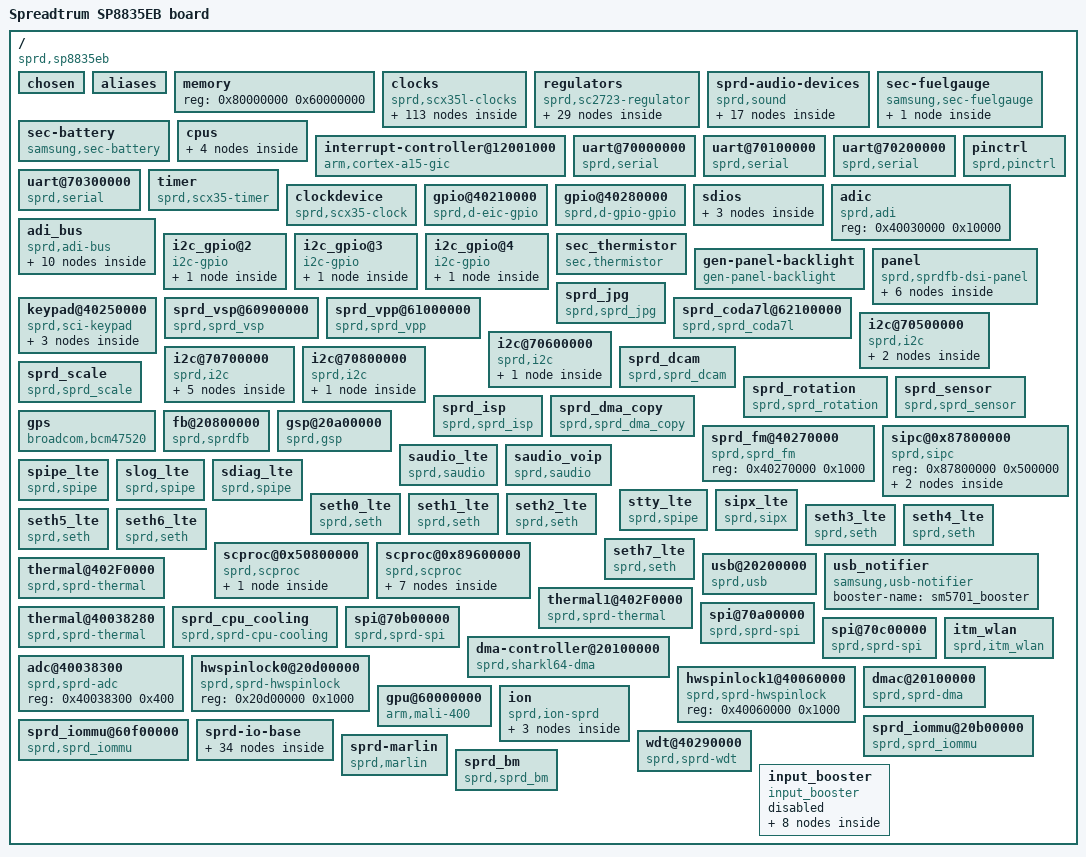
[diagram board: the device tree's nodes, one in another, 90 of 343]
/dts-v1/;

/memreserve/	0x0000000087800000 0x0000000000500000;
/memreserve/	0x0000000089600000 0x0000000004380000;
/memreserve/	0x000000009b23b000 0x0000000003939000;
/memreserve/	0x000000009eb74000 0x0000000000a8c000;
/memreserve/	0x000000009f600000 0x0000000000708000;
/ {
	#address-cells = <0x01>;
	#size-cells = <0x01>;
	model = "Spreadtrum SP8835EB board";
	compatible = "sprd,sp8835eb";
	sprd,sc-id = <0x2666 0x03 0x20000>;
	interrupt-parent = <0x01>;

	chosen {
		bootargs = "loglevel=1 init=/init root=/dev/ram0 rw";
		linux,initrd-start = <0x85500000>;
		linux,initrd-end = <0x855a3212>;
	};

	aliases {
		serial0 = "/uart@70000000";
		serial1 = "/uart@70100000";
		serial2 = "/uart@70200000";
		serial3 = "/uart@70300000";
		i2c0 = "/i2c@70500000";
		i2c1 = "/i2c@70600000";
		i2c2 = "/i2c@70700000";
		i2c3 = "/i2c@70800000";
		lcd0 = "/fb@20800000";
		spi0 = "/spi@70a00000";
		spi1 = "/spi@70b00000";
		spi2 = "/spi@70c00000";
		hwspinlock0 = "/hwspinlock0@20d00000";
		hwspinlock1 = "/hwspinlock1@40060000";
		i2c_gpio7 = "/i2c_gpio@2";
		i2c_gpio8 = "/i2c_gpio@3";
		i2c_gpio9 = "/i2c_gpio@4";
	};

	memory {
		#address-cells = <0x01>;
		#size-cells = <0x01>;
		device_type = "memory";
		reg = <0x80000000 0x60000000>;
	};

	clocks {
		compatible = "sprd,scx35l-clocks";
		#address-cells = <0x01>;
		#size-cells = <0x01>;

		ext_26m {
			compatible = "sprd,fixed-clock";
			#clock-cells = <0x00>;
			clock-frequency = <0x18cba80>;
			clock-output-names = "ext_26m";
			linux,phandle = <0x07>;
			phandle = <0x07>;
		};

		ext_32k {
			compatible = "sprd,fixed-clock";
			#clock-cells = <0x00>;
			clock-frequency = <0x8000>;
			clock-output-names = "ext_32k";
			linux,phandle = <0x11>;
			phandle = <0x11>;
		};

		ext_26m_rf1 {
			compatible = "sprd,fixed-clock";
			#clock-cells = <0x00>;
			clock-frequency = <0x18cba80>;
			clock-output-names = "ext_26m_rf1";
			linux,phandle = <0x12>;
			phandle = <0x12>;
		};

		ext_1m {
			compatible = "sprd,fixed-clock";
			#clock-cells = <0x00>;
			clock-frequency = <0xf4240>;
			clock-output-names = "ext_1m";
			linux,phandle = <0x18>;
			phandle = <0x18>;
		};

		ext_2m {
			compatible = "sprd,fixed-clock";
			#clock-cells = <0x00>;
			clock-frequency = <0x1e8480>;
			clock-output-names = "ext_2m";
		};

		ext_4m {
			compatible = "sprd,fixed-clock";
			#clock-cells = <0x00>;
			clock-frequency = <0x3d0900>;
			clock-output-names = "ext_4m";
			linux,phandle = <0x0b>;
			phandle = <0x0b>;
		};

		clk_pad {
			compatible = "sprd,fixed-clock";
			#clock-cells = <0x00>;
			clock-frequency = <0x3d09000>;
			clock-output-names = "clk_pad";
			linux,phandle = <0x28>;
			phandle = <0x28>;
		};

		clk_mpll {
			compatible = "sprd,adjustable-pll-clock";
			#clock-cells = <0x00>;
			reg = <0x402e0044 0x7ff 0x402b0094 0x01>;
			clock-output-names = "clk_mpll";
			linux,phandle = <0x04>;
			phandle = <0x04>;
		};

		clk_dpll {
			compatible = "sprd,adjustable-pll-clock";
			#clock-cells = <0x00>;
			reg = <0x402e004c 0x7ff 0x402b0098 0x01>;
			clock-output-names = "clk_dpll";
			linux,phandle = <0x03>;
			phandle = <0x03>;
		};

		clk_ltepll {
			compatible = "sprd,adjustable-pll-clock";
			#clock-cells = <0x00>;
			reg = <0x402e005c 0x7ff 0x402b009c 0x01>;
			clock-output-names = "clk_ltepll";
			linux,phandle = <0x05>;
			phandle = <0x05>;
		};

		clk_twpll {
			compatible = "sprd,adjustable-pll-clock";
			#clock-cells = <0x00>;
			reg = <0x402e0054 0x7ff 0x402b00a0 0x01>;
			clock-output-names = "clk_twpll";
			linux,phandle = <0x02>;
			phandle = <0x02>;
		};

		clk_lvdspll {
			compatible = "sprd,adjustable-pll-clock";
			#clock-cells = <0x00>;
			reg = <0x402e0064 0x7ff 0x402b00a4 0x01>;
			clock-output-names = "clk_lvdspll";
			linux,phandle = <0x06>;
			phandle = <0x06>;
		};

		clk_768m {
			compatible = "sprd,fixed-factor-clock";
			#clock-cells = <0x00>;
			clock-mult = <0x01>;
			clock-div = <0x02>;
			clocks = <0x02>;
			clock-output-names = "clk_768m";
			linux,phandle = <0x09>;
			phandle = <0x09>;
		};

		clk_512m {
			compatible = "sprd,fixed-factor-clock";
			#clock-cells = <0x00>;
			clock-mult = <0x01>;
			clock-div = <0x03>;
			clocks = <0x02>;
			clock-output-names = "clk_512m";
			linux,phandle = <0x08>;
			phandle = <0x08>;
		};

		clk_384m {
			compatible = "sprd,fixed-factor-clock";
			#clock-cells = <0x00>;
			clock-mult = <0x01>;
			clock-div = <0x04>;
			clocks = <0x02>;
			clock-output-names = "clk_384m";
			linux,phandle = <0x1c>;
			phandle = <0x1c>;
		};

		clk_312m {
			compatible = "sprd,fixed-factor-clock";
			#clock-cells = <0x00>;
			clock-mult = <0x01>;
			clock-div = <0x05>;
			clocks = <0x02>;
			clock-output-names = "clk_312m";
			linux,phandle = <0x26>;
			phandle = <0x26>;
		};

		clk_307m2 {
			compatible = "sprd,fixed-factor-clock";
			#clock-cells = <0x00>;
			clock-mult = <0x01>;
			clock-div = <0x05>;
			clocks = <0x02>;
			clock-output-names = "clk_307m2";
			linux,phandle = <0x1b>;
			phandle = <0x1b>;
		};

		clk_256m {
			compatible = "sprd,fixed-factor-clock";
			#clock-cells = <0x00>;
			clock-mult = <0x01>;
			clock-div = <0x06>;
			clocks = <0x02>;
			clock-output-names = "clk_256m";
			linux,phandle = <0x20>;
			phandle = <0x20>;
		};

		clk_192m {
			compatible = "sprd,fixed-factor-clock";
			#clock-cells = <0x00>;
			clock-mult = <0x01>;
			clock-div = <0x08>;
			clocks = <0x02>;
			clock-output-names = "clk_192m";
			linux,phandle = <0x1a>;
			phandle = <0x1a>;
		};

		clk_153m6 {
			compatible = "sprd,fixed-factor-clock";
			#clock-cells = <0x00>;
			clock-mult = <0x01>;
			clock-div = <0x0a>;
			clocks = <0x02>;
			clock-output-names = "clk_153m6";
			linux,phandle = <0x19>;
			phandle = <0x19>;
		};

		clk_128m {
			compatible = "sprd,fixed-factor-clock";
			#clock-cells = <0x00>;
			clock-mult = <0x01>;
			clock-div = <0x0c>;
			clocks = <0x02>;
			clock-output-names = "clk_128m";
			linux,phandle = <0x0d>;
			phandle = <0x0d>;
		};

		clk_96m {
			compatible = "sprd,fixed-factor-clock";
			#clock-cells = <0x00>;
			clock-mult = <0x01>;
			clock-div = <0x10>;
			clocks = <0x02>;
			clock-output-names = "clk_96m";
			linux,phandle = <0x0c>;
			phandle = <0x0c>;
		};

		clk_76m8 {
			compatible = "sprd,fixed-factor-clock";
			#clock-cells = <0x00>;
			clock-mult = <0x01>;
			clock-div = <0x14>;
			clocks = <0x02>;
			clock-output-names = "clk_76m8";
			linux,phandle = <0x0e>;
			phandle = <0x0e>;
		};

		clk_64m {
			compatible = "sprd,fixed-factor-clock";
			#clock-cells = <0x00>;
			clock-mult = <0x01>;
			clock-div = <0x18>;
			clocks = <0x02>;
			clock-output-names = "clk_64m";
			linux,phandle = <0x1f>;
			phandle = <0x1f>;
		};

		clk_51m2 {
			compatible = "sprd,fixed-factor-clock";
			#clock-cells = <0x00>;
			clock-mult = <0x01>;
			clock-div = <0x1e>;
			clocks = <0x02>;
			clock-output-names = "clk_51m2";
			linux,phandle = <0x10>;
			phandle = <0x10>;
		};

		clk_48m {
			compatible = "sprd,fixed-factor-clock";
			#clock-cells = <0x00>;
			clock-mult = <0x01>;
			clock-div = <0x20>;
			clocks = <0x02>;
			clock-output-names = "clk_48m";
			linux,phandle = <0x14>;
			phandle = <0x14>;
		};

		clk_38m4 {
			compatible = "sprd,fixed-factor-clock";
			#clock-cells = <0x00>;
			clock-mult = <0x01>;
			clock-div = <0x28>;
			clocks = <0x02>;
			clock-output-names = "clk_38m4";
			linux,phandle = <0x0f>;
			phandle = <0x0f>;
		};

		clk_24m {
			compatible = "sprd,fixed-factor-clock";
			#clock-cells = <0x00>;
			clock-mult = <0x01>;
			clock-div = <0x40>;
			clocks = <0x02>;
			clock-output-names = "clk_24m";
			linux,phandle = <0x22>;
			phandle = <0x22>;
		};

		clk_12m {
			compatible = "sprd,fixed-factor-clock";
			#clock-cells = <0x00>;
			clock-mult = <0x01>;
			clock-div = <0x80>;
			clocks = <0x02>;
			clock-output-names = "clk_12m";
			linux,phandle = <0x21>;
			phandle = <0x21>;
		};

		clk_42m_d {
			compatible = "sprd,fixed-factor-clock";
			#clock-cells = <0x00>;
			clock-mult = <0x01>;
			clock-div = <0x20>;
			clocks = <0x03>;
			clock-output-names = "clk_42m_d";
			linux,phandle = <0x13>;
			phandle = <0x13>;
		};

		clk_56m_m {
			compatible = "sprd,fixed-factor-clock";
			#clock-cells = <0x00>;
			clock-mult = <0x01>;
			clock-div = <0x20>;
			clocks = <0x04>;
			clock-output-names = "clk_56m_m";
			linux,phandle = <0x15>;
			phandle = <0x15>;
		};

		clk_38m4_lte {
			compatible = "sprd,fixed-factor-clock";
			#clock-cells = <0x00>;
			clock-mult = <0x01>;
			clock-div = <0x20>;
			clocks = <0x05>;
			clock-output-names = "clk_38m4_lte";
			linux,phandle = <0x16>;
			phandle = <0x16>;
		};

		clk_44m_lvds {
			compatible = "sprd,fixed-factor-clock";
			#clock-cells = <0x00>;
			clock-mult = <0x01>;
			clock-div = <0x20>;
			clocks = <0x06>;
			clock-output-names = "clk_44m_lvds";
			linux,phandle = <0x17>;
			phandle = <0x17>;
		};

		clk_614m4 {
			compatible = "sprd,fixed-factor-clock";
			#clock-cells = <0x00>;
			clock-mult = <0x01>;
			clock-div = <0x02>;
			clocks = <0x05>;
			clock-output-names = "clk_614m4";
			linux,phandle = <0x1d>;
			phandle = <0x1d>;
		};

		clk_mcu {
			compatible = "sprd,composite-dev-clock";
			#clock-cells = <0x00>;
			reg = <0x20e00054 0x07 0x20e00038 0x70>;
			clocks = <0x07 0x08 0x09 0x03 0x05 0x02 0x04>;
			clock-output-names = "clk_mcu";
			linux,phandle = <0x0a>;
			phandle = <0x0a>;
		};

		clk_ca7_axi {
			compatible = "sprd,divider-clock";
			#clock-cells = <0x00>;
			reg = <0x20e00038 0x700>;
			clocks = <0x0a>;
			clock-output-names = "clk_ca7_axi";
		};

		clk_ca7_dbg {
			compatible = "sprd,divider-clock";
			#clock-cells = <0x00>;
			reg = <0x20e00038 0x70000>;
			clocks = <0x0a>;
			clock-output-names = "clk_ca7_dbg";
		};

		clk_pub_ahb {
			compatible = "sprd,composite-dev-clock";
			#clock-cells = <0x00>;
			reg = <0x402d0020 0x03 0x402d0020 0x300>;
			clocks = <0x07 0x0b 0x0c 0x0d>;
			clock-output-names = "clk_pub_ahb";
		};

		clk_aon_apb {
			compatible = "sprd,composite-dev-clock";
			#clock-cells = <0x00>;
			reg = <0x402d0024 0x03 0x402d0024 0x300>;
			clocks = <0x0b 0x07 0x0e 0x0c>;
			clock-output-names = "clk_aon_apb";
			linux,phandle = <0x1e>;
			phandle = <0x1e>;
		};

		clk_adi {
			compatible = "sprd,muxed-clock";
			#clock-cells = <0x00>;
			reg = <0x402d0028 0x03 0x402e0000 0x10000>;
			clocks = <0x07 0x0b 0x0f 0x10>;
			clock-output-names = "clk_adi";
		};

		clk_aux0 {
			compatible = "sprd,muxed-clock";
			#clock-cells = <0x00>;
			reg = <0x402e0088 0x0f 0x402e0004 0x04>;
			clocks = <0x11 0x07 0x12 0x0b 0x13 0x14 0x15>;
			clock-output-names = "clk_aux0";
		};

		clk_aux1 {
			compatible = "sprd,muxed-clock";
			#clock-cells = <0x00>;
			reg = <0x402d0088 0xf0 0x402e0004 0x08>;
			clocks = <0x11 0x07 0x12 0x0b 0x13 0x14 0x15 0x16 0x17>;
			clock-output-names = "clk_aux1";
		};

		clk_aux2 {
			compatible = "sprd,muxed-clock";
			#clock-cells = <0x00>;
			reg = <0x402d0088 0xf00 0x402e0004 0x10>;
			clocks = <0x11 0x07 0x12 0x0b 0x13 0x14 0x15 0x16 0x17>;
			clock-output-names = "clk_aux2";
		};

		clk_pwm0 {
			compatible = "sprd,muxed-clock";
			#clock-cells = <0x00>;
			reg = <0x402d002c 0x03 0x402e0000 0x10>;
			clocks = <0x11 0x07 0x12 0x14>;
			clock-output-names = "clk_pwm0";
		};

		clk_pwm1 {
			compatible = "sprd,muxed-clock";
			#clock-cells = <0x00>;
			reg = <0x402d0030 0x03 0x402e0000 0x20>;
			clocks = <0x11 0x07 0x12 0x14>;
			clock-output-names = "clk_pwm1";
		};

		clk_pwm2 {
			compatible = "sprd,muxed-clock";
			#clock-cells = <0x00>;
			reg = <0x402d0034 0x03 0x402e0000 0x40>;
			clocks = <0x11 0x07 0x12 0x14>;
			clock-output-names = "clk_pwm2";
		};

		clk_pwm3 {
			compatible = "sprd,muxed-clock";
			#clock-cells = <0x00>;
			reg = <0x402d0038 0x03 0x402e0000 0x80>;
			clocks = <0x11 0x07 0x12 0x14>;
			clock-output-names = "clk_pwm3";
		};

		clk_thm {
			compatible = "sprd,muxed-clock";
			#clock-cells = <0x00>;
			reg = <0x402d0040 0x01 0x402e0004 0x02>;
			clocks = <0x11 0x18>;
			clock-output-names = "clk_thm";
		};

		clk_mspi {
			compatible = "sprd,muxed-clock";
			#clock-cells = <0x00>;
			reg = <0x402d0044 0x03 0x402e0000 0x800000>;
			clocks = <0x07 0x10 0x0e 0x0c>;
			clock-output-names = "clk_mspi";
		};

		clk_i2c {
			compatible = "sprd,muxed-clock";
			#clock-cells = <0x00>;
			reg = <0x402d0048 0x03 0x402e0000 0x80000000>;
			clocks = <0x07 0x14 0x10 0x19>;
			clock-output-names = "clk_i2c";
		};

		clk_avs {
			compatible = "sprd,muxed-clock";
			#clock-cells = <0x00>;
			reg = <0x402d004c 0x03 0x402e0004 0x40>;
			clocks = <0x07 0x14 0x10 0x0c>;
			clock-output-names = "clk_avs";
		};

		clk_audif {
			compatible = "sprd,muxed-clock";
			#clock-cells = <0x00>;
			reg = <0x402d0050 0x03 0x402e0000 0x20000>;
			clocks = <0x07 0x0f 0x10>;
			clock-output-names = "clk_audif";
		};

		clk_ca7_dap {
			compatible = "sprd,muxed-clock";
			#clock-cells = <0x00>;
			reg = <0x402d0054 0x03 0x402e0000 0x40000000>;
			clocks = <0x07 0x0e 0x0d 0x19>;
			clock-output-names = "clk_ca7_dap";
		};

		clk_emc {
			compatible = "sprd,composite-dev-clock";
			#clock-cells = <0x00>;
			reg = <0x402d0058 0x07 0x402d0058 0x700>;
			clocks = <0x07 0x1a 0x1b 0x1c 0x08 0x1d 0x09 0x03>;
			clock-output-names = "clk_emc";
		};

		clk_ca7_ts {
			compatible = "sprd,muxed-clock";
			#clock-cells = <0x00>;
			reg = <0x402d005c 0x03 0x402e0000 0x10000000>;
			clocks = <0x11 0x07 0x0d 0x19>;
			clock-output-names = "clk_ca7_ts";
		};

		clk_djtag_tck {
			compatible = "sprd,muxed-clock";
			#clock-cells = <0x00>;
			reg = <0x402d0060 0x01>;
			clocks = <0x07 0x0b>;
			clock-output-names = "clk_djtag_tck";
		};

		clk_arm7_ahb {
			compatible = "sprd,composite-dev-clock";
			#clock-cells = <0x00>;
			reg = <0x402d0064 0x03 0x402d0064 0x300>;
			clocks = <0x0b 0x07 0x0c 0x0d>;
			clock-output-names = "clk_arm7_ahb";
		};

		clk_ca5_ts {
			compatible = "sprd,muxed-clock";
			#clock-cells = <0x00>;
			reg = <0x402d0068 0x03 0x402e0004 0x4000000>;
			clocks = <0x11 0x07 0x0d 0x19>;
			clock-output-names = "clk_ca5_ts";
		};

		clk_disp_emc {
			compatible = "sprd,gate-clock";
			#clock-cells = <0x00>;
			reg = <0x402e0004 0x800>;
			clocks = <0x1e>;
			clock-output-names = "clk_disp_emc";
			linux,phandle = <0x4e>;
			phandle = <0x4e>;
		};

		clk_gsp_emc {
			compatible = "sprd,gate-clock";
			#clock-cells = <0x00>;
			reg = <0x402e0004 0x2000>;
			clocks = <0x1e>;
			clock-output-names = "clk_gsp_emc";
			linux,phandle = <0x51>;
			phandle = <0x51>;
		};

		clk_ap_ahb {
			compatible = "sprd,muxed-clock";
			#clock-cells = <0x00>;
			reg = <0x21500020 0x03>;
			clocks = <0x07 0x0e 0x0d 0x1a>;
			clock-output-names = "clk_ap_ahb";
		};

		clk_ap_apb {
			compatible = "sprd,muxed-clock";
			#clock-cells = <0x00>;
			reg = <0x21500024 0x03>;
			clocks = <0x07 0x1f 0x0c 0x0d>;
			clock-output-names = "clk_ap_apb";
		};

		clk_gsp {
			compatible = "sprd,muxed-clock";
			#clock-cells = <0x00>;
			reg = <0x21500028 0x03 0x20e00000 0x08>;
			clocks = <0x0c 0x19 0x1a 0x20>;
			clock-output-names = "clk_gsp";
			linux,phandle = <0x50>;
			phandle = <0x50>;
		};

		clk_dispc0 {
			compatible = "sprd,composite-dev-clock";
			#clock-cells = <0x00>;
			reg = <0x2150002c 0x03 0x2150002c 0x700 0x20e00000 0x02>;
			clocks = <0x19 0x1a 0x20 0x1b>;
			clock-output-names = "clk_dispc0";
			linux,phandle = <0x4b>;
			phandle = <0x4b>;
		};

		clk_dispc0_dbi {
			compatible = "sprd,composite-dev-clock";
			#clock-cells = <0x00>;
			reg = <0x21500030 0x03 0x21500030 0x700>;
			clocks = <0x0d 0x19 0x1a 0x20>;
			clock-output-names = "clk_dispc0_dbi";
			linux,phandle = <0x4c>;
			phandle = <0x4c>;
		};

		clk_dispc0_dpi {
			compatible = "sprd,composite-dev-clock";
			#clock-cells = <0x00>;
			reg = <0x21500034 0x03 0x21500034 0xff00>;
			clocks = <0x0d 0x19 0x1a 0x1c>;
			clock-output-names = "clk_dispc0_dpi";
			linux,phandle = <0x4d>;
			phandle = <0x4d>;
		};

		clk_nandc_ecc {
			compatible = "sprd,muxed-clock";
			#clock-cells = <0x00>;
			reg = <0x21500038 0x01 0x20e00000 0x80000 0x20e00000 0x20000>;
			clocks = <0x19 0x1a>;
			clock-output-names = "clk_nandc_ecc";
		};

		clk_nandc_2x {
			compatible = "sprd,composite-dev-clock";
			#clock-cells = <0x00>;
			reg = <0x20e03038 0x03 0x20e03038 0x0c 0x20e00000 0xe0000>;
			clocks = <0x1a 0x20 0x1b 0x1c>;
			clock-output-names = "clk_nandc_2x";
		};

		clk_sdio0 {
			compatible = "sprd,composite-dev-clock";
			#clock-cells = <0x00>;
			reg = <0x2150003c 0x03 0x2150003c 0x700 0x20e00000 0x100>;
			clocks = <0x07 0x20 0x1b 0x1c>;
			clock-output-names = "clk_sdio0";
			linux,phandle = <0x38>;
			phandle = <0x38>;
		};

		clk_sdio1 {
			compatible = "sprd,muxed-clock";
			#clock-cells = <0x00>;
			reg = <0x21500040 0x03 0x20e00000 0x200>;
			clocks = <0x14 0x0e 0x0c 0x0d>;
			clock-output-names = "clk_sdio1";
			linux,phandle = <0x39>;
			phandle = <0x39>;
		};

		clk_sdio2 {
			compatible = "sprd,muxed-clock";
			#clock-cells = <0x00>;
			reg = <0x21500044 0x03 0x20e00000 0x400>;
			clocks = <0x14 0x0e 0x0c 0x0d>;
			clock-output-names = "clk_sdio2";
		};

		clk_emmc {
			compatible = "sprd,muxed-clock";
			#clock-cells = <0x00>;
			reg = <0x21500048 0x03 0x20e00000 0x800>;
			clocks = <0x07 0x20 0x1b 0x1c>;
			clock-output-names = "clk_emmc";
			linux,phandle = <0x37>;
			phandle = <0x37>;
		};

		clk_otg_ref {
			compatible = "sprd,muxed-clock";
			#clock-cells = <0x00>;
			reg = <0x2150004c 0x01 0x20e00000 0x10>;
			clocks = <0x21 0x22>;
			clock-output-names = "clk_otg_ref";
		};

		clk_hsic_ref {
			compatible = "sprd,muxed-clock";
			#clock-cells = <0x00>;
			reg = <0x21500050 0x01 0x20e00000 0x04>;
			clocks = <0x21 0x22>;
			clock-output-names = "clk_hsic_ref";
		};

		clk_uart0 {
			compatible = "sprd,composite-dev-clock";
			#clock-cells = <0x00>;
			reg = <0x21500054 0x03 0x21500054 0x700 0x71300000 0x2000>;
			clocks = <0x07 0x14 0x10 0x0c>;
			clock-output-names = "clk_uart0";
		};

		clk_uart1 {
			compatible = "sprd,composite-dev-clock";
			#clock-cells = <0x00>;
			reg = <0x21500058 0x03 0x21500058 0x700 0x71300000 0x4000>;
			clocks = <0x07 0x14 0x10 0x0c>;
			clock-output-names = "clk_uart1";
		};

		clk_uart2 {
			compatible = "sprd,composite-dev-clock";
			#clock-cells = <0x00>;
			reg = <0x2150005c 0x03 0x2150005c 0x700 0x71300000 0x8000>;
			clocks = <0x07 0x14 0x10 0x0c>;
			clock-output-names = "clk_uart2";
		};

		clk_uart3 {
			compatible = "sprd,composite-dev-clock";
			#clock-cells = <0x00>;
			reg = <0x21500060 0x03 0x21500060 0x700 0x71300000 0x10000>;
			clocks = <0x07 0x14 0x10 0x0c>;
			clock-output-names = "clk_uart3";
		};

		clk_uart4 {
			compatible = "sprd,composite-dev-clock";
			#clock-cells = <0x00>;
			reg = <0x21500064 0x03 0x21500064 0x700 0x71300000 0x20000>;
			clocks = <0x07 0x14 0x10 0x0c>;
			clock-output-names = "clk_uart4";
		};

		clk_i2c0 {
			compatible = "sprd,composite-dev-clock";
			#clock-cells = <0x00>;
			reg = <0x21500068 0x03 0x21500068 0x700 0x71300000 0x100>;
			clocks = <0x07 0x14 0x10 0x19>;
			clock-output-names = "clk_i2c0";
		};

		clk_i2c1 {
			compatible = "sprd,composite-dev-clock";
			#clock-cells = <0x00>;
			reg = <0x2150006c 0x03 0x2150006c 0x700 0x71300000 0x200>;
			clocks = <0x07 0x14 0x10 0x19>;
			clock-output-names = "clk_i2c1";
		};

		clk_i2c2 {
			compatible = "sprd,composite-dev-clock";
			#clock-cells = <0x00>;
			reg = <0x21500070 0x03 0x21500070 0x700 0x71300000 0x400>;
			clocks = <0x07 0x14 0x10 0x19>;
			clock-output-names = "clk_i2c2";
		};

		clk_i2c3 {
			compatible = "sprd,composite-dev-clock";
			#clock-cells = <0x00>;
			reg = <0x21500074 0x03 0x21500074 0x700 0x71300000 0x800>;
			clocks = <0x07 0x14 0x10 0x19>;
			clock-output-names = "clk_i2c3";
		};

		clk_i2c4 {
			compatible = "sprd,composite-dev-clock";
			#clock-cells = <0x00>;
			reg = <0x21500078 0x03 0x21500078 0x700 0x71300000 0x1000>;
			clocks = <0x07 0x14 0x10 0x19>;
			clock-output-names = "clk_i2c4";
		};

		clk_spi0 {
			compatible = "sprd,composite-dev-clock";
			#clock-cells = <0x00>;
			reg = <0x2150007c 0x03 0x2150007c 0x700 0x71300000 0x20>;
			clocks = <0x07 0x0c 0x19 0x1a>;
			clock-output-names = "clk_spi0";
		};

		clk_spi1 {
			compatible = "sprd,composite-dev-clock";
			#clock-cells = <0x00>;
			reg = <0x21500080 0x03 0x21500080 0x700 0x71300000 0x40>;
			clocks = <0x07 0x0c 0x19 0x1a>;
			clock-output-names = "clk_spi1";
		};

		clk_spi2 {
			compatible = "sprd,composite-dev-clock";
			#clock-cells = <0x00>;
			reg = <0x21500084 0x03 0x21500084 0x700 0x71300000 0x80>;
			clocks = <0x07 0x0c 0x19 0x1a>;
			clock-output-names = "clk_spi2";
			linux,phandle = <0x4f>;
			phandle = <0x4f>;
		};

		clk_iis0 {
			compatible = "sprd,composite-dev-clock";
			#clock-cells = <0x00>;
			reg = <0x21500088 0x03 0x21500088 0x700 0x71300000 0x02>;
			clocks = <0x07 0x0d 0x19>;
			clock-output-names = "clk_iis0";
		};

		clk_iis1 {
			compatible = "sprd,composite-dev-clock";
			#clock-cells = <0x00>;
			reg = <0x2150008c 0x03 0x2150008c 0x700 0x71300000 0x04>;
			clocks = <0x07 0x0d 0x19>;
			clock-output-names = "clk_iis1";
		};

		clk_iis2 {
			compatible = "sprd,composite-dev-clock";
			#clock-cells = <0x00>;
			reg = <0x21500090 0x03 0x21500090 0x700 0x71300000 0x08>;
			clocks = <0x07 0x0d 0x19>;
			clock-output-names = "clk_iis2";
		};

		clk_iis3 {
			compatible = "sprd,composite-dev-clock";
			#clock-cells = <0x00>;
			reg = <0x21500094 0x03 0x21500094 0x700 0x71300000 0x10>;
			clocks = <0x07 0x0d 0x19>;
			clock-output-names = "clk_iis3";
		};

		clk_zipenc {
			compatible = "sprd,muxed-clock";
			#clock-cells = <0x00>;
			reg = <0x21500098 0x03 0x20e00000 0x100000>;
			clocks = <0x0c 0x19 0x1a 0x20>;
			clock-output-names = "clk_zipenc";
		};

		clk_zipdec {
			compatible = "sprd,muxed-clock";
			#clock-cells = <0x00>;
			reg = <0x2150009c 0x03 0x20e00000 0x200000>;
			clocks = <0x0c 0x19 0x1a 0x20>;
			clock-output-names = "clk_zipdec";
		};

		clk_gpu_axi {
			compatible = "sprd,gate-clock";
			#clock-cells = <0x00>;
			reg = <0x402e0000 0x8000000 0x402b0021 0x2000000>;
			clocks = <0x1e>;
			clock-output-names = "clk_gpu_axi";
			linux,phandle = <0x53>;
			phandle = <0x53>;
		};

		clk_gpu {
			compatible = "sprd,composite-dev-clock";
			#clock-cells = <0x00>;
			reg = <0x60100004 0x07 0x60100004 0x30>;
			clocks = <0x19 0x1a 0x20 0x1b 0x1c 0x08>;
			clock-output-names = "clk_gpu";
			linux,phandle = <0x54>;
			phandle = <0x54>;
		};

		clk_mm {
			compatible = "sprd,gate-clock";
			#clock-cells = <0x00>;
			reg = <0x402e0000 0x2000000 0x402b001d 0x2000000>;
			clocks = <0x1e>;
			clock-output-names = "clk_mm";
			linux,phandle = <0x23>;
			phandle = <0x23>;
		};

		clk_mm_ahb {
			compatible = "sprd,muxed-clock";
			#clock-cells = <0x00>;
			reg = <0x60e00020 0x03>;
			clocks = <0x07 0x0c 0x0d 0x19>;
			clock-output-names = "clk_mm_ahb";
			mm-domain;
			linux,phandle = <0x25>;
			phandle = <0x25>;
		};

		clk_mm_axi {
			compatible = "sprd,gate-clock";
			#clock-cells = <0x00>;
			reg = <0x60d00008 0x80>;
			clocks = <0x23>;
			clock-output-names = "clk_mm_axi";
			#mm-domain;
			linux,phandle = <0x24>;
			phandle = <0x24>;
		};

		clk_mm_mtx_axi {
			compatible = "sprd,gate-clock";
			#clock-cells = <0x00>;
			reg = <0x60d00008 0x100>;
			clocks = <0x24>;
			clock-output-names = "clk_mm_mtx_axi";
			mm-domain;
		};

		clk_mmu {
			compatible = "sprd,gate-clock";
			#clock-cells = <0x00>;
			reg = <0x60d00000 0x80>;
			clocks = <0x25>;
			clock-output-names = "clk_mmu";
			mm-domain;
			linux,phandle = <0x55>;
			phandle = <0x55>;
		};

		clk_mm_ckg {
			compatible = "sprd,gate-clock";
			#clock-cells = <0x00>;
			reg = <0x60d00000 0x40>;
			clocks = <0x25>;
			clock-output-names = "clk_mm_ckg";
			mm-domain;
		};

		clk_jpg {
			compatible = "sprd,muxed-clock";
			#clock-cells = <0x00>;
			reg = <0x60e00038 0x03 0x60d00008 0x40 0x60d00000 0x20>;
			clocks = <0x0e 0x0d 0x20 0x26>;
			clock-output-names = "clk_jpg";
			mm-domain;
			linux,phandle = <0x41>;
			phandle = <0x41>;
		};

		clk_vpp {
			compatible = "sprd,muxed-clock";
			#clock-cells = <0x00>;
			reg = <0x60e00048 0x03 0x60d00008 0x200 0x60d00000 0x100>;
			clocks = <0x0e 0x0d 0x1a 0x20>;
			clock-output-names = "clk_vpp";
			mm-domain;
			linux,phandle = <0x42>;
			phandle = <0x42>;
		};

		clk_coda7_axi {
			compatible = "sprd,muxed-clock";
			#clock-cells = <0x00>;
			reg = <0x62000008 0x300 0x62000004 0x01 0x402e0004 0x10000000>;
			clocks = <0x0e 0x0d 0x19 0x1a>;
			clock-output-names = "clk_coda7_axi";
			mm_domain;
			linux,phandle = <0x43>;
			phandle = <0x43>;
		};

		clk_coda7_cc {
			compatible = "sprd,muxed-clock";
			#clock-cells = <0x00>;
			reg = <0x62000008 0x30 0x62000004 0x02 0x402e0004 0x10000000>;
			clocks = <0x0e 0x0d 0x19 0x1a>;
			clock-output-names = "clk_coda7_cc";
			mm_domain;
			linux,phandle = <0x44>;
			phandle = <0x44>;
		};

		clk_coda7_apb {
			compatible = "sprd,muxed-clock";
			#clock-cells = <0x00>;
			reg = <0x62000008 0x03 0x62000004 0x10 0x402e0004 0x10000000>;
			clocks = <0x07 0x0e 0x0c 0x0d>;
			clock-output-names = "clk_coda7_apb";
			mm_domain;
			linux,phandle = <0x45>;
			phandle = <0x45>;
		};

		clk_csi {
			compatible = "sprd,gate-clock";
			#clock-cells = <0x00>;
			reg = <0x60d00008 0x02 0x60d00000 0x10>;
			clocks = <0x25>;
			clock-output-names = "clk_csi";
			mm-domain;
			linux,phandle = <0x27>;
			phandle = <0x27>;
		};

		clk_dcam_mipi {
			compatible = "sprd,gate-clock";
			#clock-cells = <0x00>;
			reg = <0x60d00008 0x01>;
			clocks = <0x27>;
			clock-output-names = "clk_dcam_mipi";
			mm-domain;
			linux,phandle = <0x49>;
			phandle = <0x49>;
		};

		clk_vsp {
			compatible = "sprd,muxed-clock";
			#clock-cells = <0x00>;
			reg = <0x60e00030 0x03 0x60d00008 0x20 0x60d00000 0x08>;
			clocks = <0x0e 0x0d 0x20 0x26>;
			clock-output-names = "clk_vsp";
			mm-domain;
			linux,phandle = <0x40>;
			phandle = <0x40>;
		};

		clk_isp {
			compatible = "sprd,muxed-clock";
			#clock-cells = <0x00>;
			reg = <0x60e00034 0x03 0x60d00008 0x10 0x60d00000 0x04>;
			clocks = <0x0e 0x0d 0x20 0x26>;
			clock-output-names = "clk_isp";
			mm-domain;
			linux,phandle = <0x4a>;
			phandle = <0x4a>;
		};

		clk_ccir {
			compatible = "sprd,muxed-clock";
			#clock-cells = <0x00>;
			reg = <0x60e00028 0x10000 0x60d00000 0x02>;
			clocks = <0x22 0x28>;
			clock-output-names = "clk_ccir";
			mm-domain;
			linux,phandle = <0x48>;
			phandle = <0x48>;
		};

		clk_sensor {
			compatible = "sprd,composite-dev-clock";
			#clock-cells = <0x00>;
			reg = <0x60e00024 0x03 0x60e00024 0x700 0x60d00008 0x04>;
			clocks = <0x07 0x14 0x0e 0x0c>;
			clock-output-names = "clk_sensor";
			mm-domain;
			linux,phandle = <0x47>;
			phandle = <0x47>;
		};

		clk_dcam {
			compatible = "sprd,muxed-clock";
			#clock-cells = <0x00>;
			reg = <0x60e0002c 0x03 0x60d00008 0x08 0x60d00000 0x01>;
			clocks = <0x0e 0x0d 0x20 0x26>;
			clock-output-names = "clk_dcam";
			mm-domain;
			linux,phandle = <0x46>;
			phandle = <0x46>;
		};
	};

	regulators {
		compatible = "sprd,sc2723-regulator";
		#address-cells = <0x01>;
		#size-cells = <0x01>;

		dummy {
		};

		vddcore {
			regulator-name = "vddcore";
			reg = <0x40038810 0x200 0x40038a00 0x3ff 0x400388c0 0x01>;
			regulator-cal-channel = <0x40038888 0x4000 0x0d>;
			regulator-default-microvolt = <0xdbba0>;
			regulator-step-microvolt = <0xc35>;
			regulator-min-microvolt = <0x927c0>;
			regulator-max-microvolt = <0x2faf08>;
			regulator-microvolt-offset = <0x00>;
			hide-offset = <0x3e8>;
			default-on;
			dcdc;
		};

		vddarm {
			regulator-name = "vddarm";
			reg = <0x40038810 0x400 0x40038a04 0x3ff 0x400388c0 0x04>;
			regulator-cal-channel = <0x40038888 0x2000 0x0d>;
			regulator-default-microvolt = <0xdbba0>;
			regulator-step-microvolt = <0xc35>;
			regulator-min-microvolt = <0x927c0>;
			regulator-max-microvolt = <0x2faf08>;
			regulator-microvolt-offset = <0x00>;
			hide-offset = <0x3e8>;
			default-on;
			dcdc;
		};

		vddmem {
			regulator-name = "vddmem";
			reg = <0x40038810 0x800 0x40038a08 0x3ff 0x400388c0 0x08>;
			regulator-cal-channel = <0x40038888 0x6000 0x0d>;
			regulator-default-microvolt = <0x124f80>;
			regulator-step-microvolt = <0xc35>;
			regulator-min-microvolt = <0x927c0>;
			regulator-max-microvolt = <0x2faf08>;
			regulator-microvolt-offset = <0x00>;
			hide-offset = <0x3e8>;
			dcdc;
		};

		vddgen {
			regulator-name = "vddgen";
			reg = <0x40038810 0x1000 0x40038a0c 0x3ff 0x400388c0 0x10>;
			regulator-cal-channel = <0x40038888 0x8000 0x0d>;
			regulator-default-microvolt = <0x249f00>;
			regulator-step-microvolt = <0xc35>;
			regulator-min-microvolt = <0x927c0>;
			regulator-max-microvolt = <0x2faf08>;
			regulator-microvolt-offset = <0x00>;
			hide-offset = <0x3e8>;
			default-on;
			dcdc;
		};

		vddrf {
			regulator-name = "vddrf";
			reg = <0x40038810 0x2000 0x40038a1c 0x3ff 0x400388c0 0x20>;
			regulator-cal-channel = <0x40038888 0xa000 0x0d>;
			regulator-default-microvolt = <0x16e360>;
			regulator-step-microvolt = <0xc35>;
			regulator-min-microvolt = <0x927c0>;
			regulator-max-microvolt = <0x2faf08>;
			regulator-microvolt-offset = <0x00>;
			hide-offset = <0x3e8>;
			default-on;
			dcdc;
		};

		vddwpa {
			regulator-name = "vddwpa";
			reg = <0x40038814 0x4000 0x40038a10 0x07 0x00 0x00>;
			regulator-cal-channel = <0x40038888 0xe000 0x0d>;
			regulator-step-microvolt = <0xc35>;
			regulator-min-microvolt = <0x2faf08>;
			regulator-max-microvolt = <0x33e140>;
			regulator-microvolt-offset = <0x00>;
			hide-offset = <0x3e8>;
			dcdc;
		};

		vddcon {
			regulator-name = "vddcon";
			reg = <0x40038814 0x2000 0x40038a18 0x3ff 0x00 0x00>;
			regulator-cal-channel = <0x40038888 0xc000 0x0d>;
			regulator-default-microvolt = <0x186a00>;
			regulator-step-microvolt = <0xc35>;
			regulator-min-microvolt = <0x927c0>;
			regulator-max-microvolt = <0x2faf08>;
			regulator-microvolt-offset = <0x00>;
			hide-offset = <0x3e8>;
			dcdc;
		};

		vddrf0 {
			regulator-name = "vddrf0";
			reg = <0x40038810 0x100 0x40038818 0x7f00 0x400388c0 0x800>;
			regulator-cal-channel = <0x40038844 0x04 0x15>;
			regulator-default-microvolt = <0x1b7740>;
			regulator-step-microvolt = <0x186a>;
			regulator-min-microvolt = <0x118c30>;
			regulator-max-microvolt = <0x1da5d8>;
			regulator-microvolt-offset = <0x00>;
			hide-offset = <0x3e8>;
			default-on;
			vol-tagert = <0x1b7740>;
		};

		vddemmccore {
			regulator-name = "vddemmccore";
			reg = <0x40038810 0x80 0x40038834 0xff00 0x400388c0 0x80>;
			regulator-cal-channel = <0x40038844 0x60 0x17>;
			regulator-default-microvolt = <0x2dc6c0>;
			regulator-step-microvolt = <0x2710>;
			regulator-min-microvolt = <0x124f80>;
			regulator-max-microvolt = <0x395f80>;
			regulator-microvolt-offset = <0x00>;
			hide-offset = <0x3e8>;
			default-on;
		};

		vddgen1 {
			regulator-name = "vddgen1";
			reg = <0x40038810 0x40 0x40038824 0x7f00 0x400388c0 0x1000>;
			regulator-cal-channel = <0x40038844 0x05 0x15>;
			regulator-default-microvolt = <0x1b7740>;
			regulator-step-microvolt = <0x186a>;
			regulator-min-microvolt = <0x118c30>;
			regulator-max-microvolt = <0x1dc130>;
			regulator-microvolt-offset = <0x00>;
			hide-offset = <0x3e8>;
			default-on;
		};

		vddgen0 {
			regulator-name = "vddgen0";
			reg = <0x40038810 0x10 0x40038820 0x7f 0x400388c0 0x2000>;
			regulator-cal-channel = <0x40038844 0x06 0x15>;
			regulator-default-microvolt = <0x1b7740>;
			regulator-step-microvolt = <0x186a>;
			regulator-min-microvolt = <0x118c30>;
			regulator-max-microvolt = <0x1dc130>;
			regulator-microvolt-offset = <0x00>;
			hide-offset = <0x3e8>;
			default-on;
		};

		vdddcxo {
			regulator-name = "vdddcxo";
			reg = <0x40038810 0x20 0x40038838 0xff00 0x400388c0 0x100>;
			regulator-cal-channel = <0x40038844 0x80 0x17>;
			regulator-default-microvolt = <0x1b7740>;
			regulator-step-microvolt = <0x2710>;
			regulator-min-microvolt = <0x124f80>;
			regulator-max-microvolt = <0x395f80>;
			regulator-microvolt-offset = <0x00>;
			hide-offset = <0x3e8>;
			default-on;
		};

		vdd25 {
			regulator-name = "vdd25";
			reg = <0x40038810 0x08 0x40038840 0xff 0x400388c0 0x40>;
			regulator-cal-channel = <0x40038844 0x100 0x16>;
			regulator-default-microvolt = <0x2ab980>;
			regulator-step-microvolt = <0x2710>;
			regulator-min-microvolt = <0x124f80>;
			regulator-max-microvolt = <0x395f80>;
			regulator-microvolt-offset = <0x00>;
			hide-offset = <0x3e8>;
		};

		vdd28 {
			regulator-name = "vdd28";
			reg = <0x40038810 0x04 0x40038824 0xff 0x400388c0 0x200>;
			regulator-cal-channel = <0x40038844 0xc0 0x17>;
			regulator-default-microvolt = <0x2ab980>;
			regulator-step-microvolt = <0x2710>;
			regulator-min-microvolt = <0x124f80>;
			regulator-max-microvolt = <0x395f80>;
			regulator-microvolt-offset = <0x00>;
			hide-offset = <0x3e8>;
			default-on;
			linux,phandle = <0x3a>;
			phandle = <0x3a>;
		};

		vdd18 {
			regulator-name = "vdd18";
			reg = <0x40038810 0x02 0x4003883c 0x7f00 0x400388c0 0x400>;
			regulator-cal-channel = <0x40038844 0x01 0x15>;
			regulator-default-microvolt = <0x1b7740>;
			regulator-step-microvolt = <0x186a>;
			regulator-min-microvolt = <0x118c30>;
			regulator-max-microvolt = <0x1dc130>;
			regulator-microvolt-offset = <0x00>;
			hide-offset = <0x3e8>;
			default-on;
		};

		vddwifipa {
			regulator-name = "vddwifipa";
			reg = <0x40038814 0x800 0x40038818 0xff 0x00 0x00>;
			regulator-cal-channel = <0x40038844 0x20 0x17>;
			regulator-default-microvolt = <0x325aa0>;
			regulator-step-microvolt = <0x2710>;
			regulator-min-microvolt = <0x124f80>;
			regulator-max-microvolt = <0x395f80>;
			regulator-microvolt-offset = <0x00>;
			hide-offset = <0x3e8>;
		};

		vddsdcore {
			regulator-name = "vddsdcore";
			reg = <0x40038814 0x400 0x40038830 0xff00 0x00 0x00>;
			regulator-cal-channel = <0x40038844 0xa0 0x17>;
			regulator-default-microvolt = <0x2dc6c0>;
			regulator-step-microvolt = <0x2710>;
			regulator-min-microvolt = <0x124f80>;
			regulator-max-microvolt = <0x395f80>;
			regulator-microvolt-offset = <0x00>;
			hide-offset = <0x3e8>;
		};

		vddsdio {
			regulator-name = "vddsdio";
			reg = <0x40038814 0x01 0x40038828 0xff 0x00 0x00>;
			regulator-cal-channel = <0x40038844 0x08 0x1d>;
			regulator-default-microvolt = <0x2dc6c0>;
			regulator-step-microvolt = <0x2710>;
			regulator-min-microvolt = <0x124f80>;
			regulator-max-microvolt = <0x395f80>;
			regulator-microvolt-offset = <0x00>;
			hide-offset = <0x3e8>;
		};

		vddsim0 {
			regulator-name = "vddsim0";
			reg = <0x40038814 0x02 0x40038828 0xff00 0x00 0x00>;
			regulator-cal-channel = <0x40038844 0x500 0x16>;
			regulator-default-microvolt = <0x1b7740>;
			regulator-step-microvolt = <0x2710>;
			regulator-min-microvolt = <0x124f80>;
			regulator-max-microvolt = <0x395f80>;
			regulator-microvolt-offset = <0x00>;
			hide-offset = <0x3e8>;
		};

		vddsim1 {
			regulator-name = "vddsim1";
			reg = <0x40038814 0x04 0x4003882c 0xff 0x00 0x00>;
			regulator-cal-channel = <0x40038844 0x400 0x16>;
			regulator-default-microvolt = <0x1b7740>;
			regulator-step-microvolt = <0x2710>;
			regulator-min-microvolt = <0x124f80>;
			regulator-max-microvolt = <0x395f80>;
			regulator-microvolt-offset = <0x00>;
			hide-offset = <0x3e8>;
		};

		vddsim2 {
			regulator-name = "vddsim2";
			reg = <0x40038814 0x08 0x4003882c 0xff00 0x00 0x00>;
			regulator-cal-channel = <0x40038844 0x300 0x16>;
			regulator-default-microvolt = <0x1b7740>;
			regulator-step-microvolt = <0x2710>;
			regulator-min-microvolt = <0x124f80>;
			regulator-max-microvolt = <0x395f80>;
			regulator-microvolt-offset = <0x00>;
			hide-offset = <0x3e8>;
		};

		vddcama {
			regulator-name = "vddcama";
			reg = <0x40038814 0x10 0x40038830 0xff 0x00 0x00>;
			regulator-cal-channel = <0x40038844 0x200 0x16>;
			regulator-default-microvolt = <0x2ab980>;
			regulator-step-microvolt = <0x2710>;
			regulator-min-microvolt = <0x124f80>;
			regulator-max-microvolt = <0x395f80>;
			regulator-microvolt-offset = <0x00>;
			hide-offset = <0x3e8>;
		};

		vddcamd {
			regulator-name = "vddcamd";
			reg = <0x40038814 0x20 0x4003881c 0x7f 0x00 0x00>;
			regulator-cal-channel = <0x40038844 0x02 0x15>;
			regulator-default-microvolt = <0x16e360>;
			regulator-step-microvolt = <0x186a>;
			regulator-min-microvolt = <0x118c30>;
			regulator-max-microvolt = <0x1dc130>;
			regulator-microvolt-offset = <0x00>;
			hide-offset = <0x3e8>;
		};

		vddcamio {
			regulator-name = "vddcamio";
			reg = <0x40038814 0x40 0x4003881c 0x7f00 0x00 0x00>;
			regulator-cal-channel = <0x40038844 0x03 0x15>;
			regulator-default-microvolt = <0x1b7740>;
			regulator-step-microvolt = <0x186a>;
			regulator-min-microvolt = <0x118c30>;
			regulator-max-microvolt = <0x1dc130>;
			regulator-microvolt-offset = <0x00>;
			hide-offset = <0x3e8>;
		};

		vddcammot {
			regulator-name = "vddcammot";
			reg = <0x40038814 0x80 0x40038834 0xff 0x00 0x00>;
			regulator-cal-channel = <0x40038844 0x40 0x17>;
			regulator-default-microvolt = <0x2ab980>;
			regulator-step-microvolt = <0x2710>;
			regulator-min-microvolt = <0x124f80>;
			regulator-max-microvolt = <0x395f80>;
			regulator-microvolt-offset = <0x00>;
			hide-offset = <0x3e8>;
		};

		vddusb {
			regulator-name = "vddusb";
			reg = <0x40038814 0x100 0x4003883c 0xff 0x00 0x00>;
			regulator-cal-channel = <0x40038844 0x10 0x1d>;
			regulator-default-microvolt = <0x325aa0>;
			regulator-step-microvolt = <0x2710>;
			regulator-min-microvolt = <0x124f80>;
			regulator-max-microvolt = <0x395f80>;
			regulator-microvolt-offset = <0x00>;
			hide-offset = <0x3e8>;
			linux,phandle = <0x52>;
			phandle = <0x52>;
		};

		vddkpled {
			regulator-name = "vddkpled";
			reg = <0x400388f4 0x100 0x400388f4 0xff 0x00 0x00>;
			regulator-cal-channel = <0x400388f8 0x3000 0x18>;
			regulator-default-microvolt = <0x325aa0>;
			regulator-step-microvolt = <0x2710>;
			regulator-min-microvolt = <0x124f80>;
			regulator-max-microvolt = <0x395f80>;
			regulator-microvolt-offset = <0x00>;
			hide-offset = <0x3e8>;
			linux,phandle = <0x3f>;
			phandle = <0x3f>;
		};

		vddvibr {
			regulator-name = "vddvibr";
			reg = <0x400388f8 0x100 0x400388f8 0xff 0x00 0x00>;
			regulator-cal-channel = <0x400388f8 0x2000 0x18>;
			regulator-default-microvolt = <0x2dc6c0>;
			regulator-step-microvolt = <0x2710>;
			regulator-min-microvolt = <0x124f80>;
			regulator-max-microvolt = <0x395f80>;
			regulator-microvolt-offset = <0x00>;
			hide-offset = <0x3e8>;
		};
	};

	sprd-audio-devices {
		compatible = "sprd,sound";
		#address-cells = <0x01>;
		#size-cells = <0x01>;

		sprd-codec {
			compatible = "sprd,sprd-codec";
			status = "okay";
			sprd,def_da_fs = <0xac44>;
			sprd,ap_irq = <0xa4>;
			sprd,dp_irq = <0x34>;
			sprd,reg_dp = <0x40000000 0x2000>;
			interrupt-parent = <0x29>;
			interrupts = <0x07 0x00>;
			sprd,audio_power_ver = <0x04>;
			linux,phandle = <0x2c>;
			phandle = <0x2c>;
		};

		sprd-codec-v3 {
			compatible = "sprd,sprd-codec-v3";
			status = "disable";
			sprd,def_da_fs = <0xac44>;
			sprd,ap_irq = <0xa4>;
			sprd,dp_irq = <0x34>;
			sprd,reg_dp = <0x40000000 0x2000>;
			interrupt-parent = <0x29>;
			interrupts = <0x07 0x00>;
			linux,phandle = <0x2e>;
			phandle = <0x2e>;
		};

		sprd-codec-v1 {
			compatible = "sprd,sprd-codec-v1";
			status = "disable";
			sprd,def_da_fs = <0xac44>;
			sprd,ap_irq = <0x67>;
			sprd,dp_irq = <0x3f>;
		};

		null-codec {
			compatible = "sprd,null-codec";
			linux,phandle = <0x33>;
			phandle = <0x33>;
		};

		vbc-r2p0 {
			compatible = "sprd,vbc-r2p0";
			status = "okay";
			sprd,reg_vbc = <0x40020000 0x20000>;
			linux,phandle = <0x2b>;
			phandle = <0x2b>;
		};

		vbc-r1p0 {
			compatible = "sprd,vbc-r1p0";
			status = "disable";
		};

		vaudio {
			compatible = "sprd,vaudio";
			linux,phandle = <0x2a>;
			phandle = <0x2a>;
		};

		bt-i2s-config {
			sprd,def_pcm_config;
		};

		fm-i2s-config {
		};

		i2s@0 {
			compatible = "sprd,i2s";
			status = "okay";
			sprd,dai_name = "i2s_bt_sco0";
			sprd,id = <0x00>;
			sprd,hw_port = <0x00>;
			sprd,base = <0x70d00000 0x100000>;
			sprd,dma_rx_no = <0x03>;
			sprd,dma_tx_no = <0x04>;
			sprd,config_type = "pcm";
			sprd,slave_timeout = <0xf11>;
			sprd,_hw_port = <0x00>;
			sprd,fs = <0x1f40>;
			sprd,bus_type = <0x01>;
			sprd,rtx_mode = <0x03>;
			sprd,byte_per_chan = <0x01>;
			sprd,slave_mode = <0x00>;
			sprd,lsb = <0x00>;
			sprd,lrck = <0x00>;
			sprd,low_for_left = <0x01>;
			sprd,clk_inv = <0x00>;
			sprd,pcm_short_frame = <0x01>;
			sprd,pcm_slot = <0x01>;
			sprd,pcm_cycle = <0x01>;
			sprd,tx_watermark = <0x0c>;
			sprd,rx_watermark = <0x14>;
			linux,phandle = <0x2f>;
			phandle = <0x2f>;
		};

		i2s@1 {
			compatible = "sprd,i2s";
			status = "okay";
			sprd,dai_name = "i2s_bt_sco1";
			sprd,id = <0x01>;
			sprd,hw_port = <0x01>;
			sprd,base = <0x70e00000 0x100000>;
			sprd,dma_rx_no = <0x05>;
			sprd,dma_tx_no = <0x06>;
			linux,phandle = <0x30>;
			phandle = <0x30>;
		};

		i2s@2 {
			compatible = "sprd,i2s";
			status = "okay";
			sprd,dai_name = "i2s_bt_sco2";
			sprd,id = <0x02>;
			sprd,hw_port = <0x02>;
			sprd,base = <0x70f00000 0x100000>;
			sprd,dma_rx_no = <0x07>;
			sprd,dma_tx_no = <0x08>;
			linux,phandle = <0x31>;
			phandle = <0x31>;
		};

		i2s@3 {
			compatible = "sprd,i2s";
			status = "okay";
			sprd,dai_name = "i2s_bt_sco3";
			sprd,id = <0x03>;
			sprd,hw_port = <0x03>;
			sprd,base = <0x71000000 0x100000>;
			sprd,dma_rx_no = <0x09>;
			sprd,dma_tx_no = <0x0a>;
			linux,phandle = <0x32>;
			phandle = <0x32>;
		};

		sprd-pcm-audio {
			compatible = "sprd,sprd-pcm";
			linux,phandle = <0x2d>;
			phandle = <0x2d>;
		};

		sound@0 {
			compatible = "sprd,vbc-r2p0-sprd-codec";
			sprd,model = "sprdphone";
			sprd,vaudio = <0x2a>;
			sprd,vbc = <0x2b>;
			sprd,codec = <0x2c>;
			sprd,pcm = <0x2d>;
		};

		sound@1 {
			compatible = "sprd,vbc-r2p0-sprd-codec-v3";
			sprd,model = "sprdphone";
			sprd,vaudio = <0x2a>;
			sprd,vbc = <0x2b>;
			sprd,codec = <0x2e>;
			sprd,pcm = <0x2d>;
		};

		sound@2 {
			compatible = "sprd,i2s-null-codec";
			sprd,model = "all-i2s";
			sprd,i2s = <0x2f 0x30 0x31 0x32>;
			sprd,codec = <0x33>;
			sprd,pcm = <0x2d>;
		};
	};

	sec-fuelgauge {
		compatible = "samsung,sec-fuelgauge";
		capacity-max = <0x3e8>;
		capacity-max-margin = <0x3e8>;
		capacity-min = <0x0a>;
		fg-irq-attr = <0x00>;
		fuel-alert-soc = <0x3e8>;
		temp_adc_channel = <0x00>;
		gpios = <0x34 0x00 0x00>;
		soft_vbat_uvlo = <0xbea>;
		vmode = <0x00>;
		alm_soc = <0x05>;
		alm_vbat = <0xd7a>;
		rint = <0xe6>;
		cnom = <0xa28>;
		rsense_real = <0xc7>;
		rsense_spec = <0xc8>;
		relax_current = <0x32>;
		cal_ajust = <0x00>;
		cnom_temp_tab = <0x401 0xa28 0x3f2 0x960 0x3e8 0x92e>;
		rint_temp_tab = <0x401 0xe6 0x3f2 0x1ae 0x3e8 0x1f4>;
		ocv_table = <0x10bd 0x64 0x1097 0x5f 0x1060 0x5a 0x102b 0x55 0xff8 0x50 0xfcc 0x4b 0xf9a 0x46 0xf77 0x41 0xf53 0x3c 0xf21 0x37 0xefe 0x32 0xee8 0x2d 0xed7 0x28 0xec9 0x23 0xebf 0x1e 0xeb8 0x19 0xea6 0x14 0xe81 0x0f 0xe69 0x0a 0xe59 0x05 0xd48 0x00>;

		sprd_fgu {
			compatible = "sprd,sprd_fgu";
			interrupt-parent = <0x29>;
			interrupts = <0x04 0x00>;
		};
	};

	sec-battery {
		compatible = "samsung,sec-battery";
		battery,vendor = "SDI SDI";
		battery,charger_name = "sec-charger";
		battery,fuelgauge_name = "sec-fuelgauge";
		battery,technology = <0x02>;
		battery,chip_vendor = "SPRD";
		battery,temp_adc_type = <0x01>;
		battery,polling_time = <0x0a 0x1e 0x1e 0x1e 0xe10>;
		battery,adc_check_count = <0x05>;
		battery,cable_check_type = <0x04>;
		battery,cable_source_type = <0x03>;
		battery,event_waiting_time = <0x258>;
		battery,polling_type = <0x01>;
		battery,monitor_initial_count = <0x03>;
		battery,battery_check_type = <0x05>;
		battery,check_count = <0x00>;
		battery,check_adc_max = <0x5a0>;
		battery,check_adc_min = <0x00>;
		battery,ovp_uvlo_check_type = <0x04>;
		battery,thermal_source = <0x02>;
		battery,temp_table_adc = <0x186 0x1c2 0x209 0x24d 0x293 0x2dd 0x352 0x383 0x3c9 0x3fc 0x41a 0x461 0x4ad 0x4d1 0x51f 0x5de 0x694 0x78a 0x861 0x94f 0xa3b 0xb0c 0xbdf 0xc1d 0xc50 0xcb8 0xcf5 0xd10 0xd67 0xda5 0xe07 0xe91 0xf14 0xfc3 0x1072>;
		battery,temp_table_data = <0x384 0x352 0x320 0x2ee 0x2bc 0x28a 0x258 0x244 0x226 0x212 0x208 0x1f4 0x1e0 0x1d6 0x1c2 0x190 0x15e 0x12c 0xfa 0xc8 0x96 0x64 0x32 0x1e 0x14 0x00 0xffffffec 0xffffffe2 0xffffffce 0xffffffba 0xffffff9c 0xffffff6a 0xffffff38 0xffffff06 0xfffffed4>;
		battery,temp_check_type = <0x02>;
		battery,temp_check_count = <0x01>;
		battery,temp_high_threshold_event = <0x226>;
		battery,temp_high_recovery_event = <0x1f4>;
		battery,temp_low_threshold_event = <0xffffffce>;
		battery,temp_low_recovery_event = <0x00>;
		battery,temp_high_threshold_normal = <0x226>;
		battery,temp_high_recovery_normal = <0x1f4>;
		battery,temp_low_threshold_normal = <0xffffffce>;
		battery,temp_low_recovery_normal = <0x00>;
		battery,temp_high_threshold_lpm = <0x226>;
		battery,temp_high_recovery_lpm = <0x1f4>;
		battery,temp_low_threshold_lpm = <0xffffffce>;
		battery,temp_low_recovery_lpm = <0x00>;
		battery,full_check_type = <0x07>;
		battery,full_check_type_2nd = <0x07>;
		battery,full_check_count = <0x01>;
		battery,chg_gpio_full_check = <0x00>;
		battery,chg_polarity_full_check = <0x01>;
		battery,full_condition_type = <0x0f>;
		battery,full_condition_soc = <0x64>;
		battery,full_condition_vcell = <0x108e>;
		battery,recharge_check_count = <0x05>;
		battery,recharge_condition_type = <0x04>;
		battery,recharge_condition_soc = <0x5f>;
		battery,recharge_condition_vcell = <0x10ac>;
		battery,charging_total_time = <0x5460>;
		battery,recharging_total_time = <0x1518>;
		battery,charging_reset_time = <0x00>;
		battery,chg_irq_attr = <0x03>;
		battery,always_enable;
		battery,swelling_high_temp_block = <0x1c2>;
		battery,swelling_high_temp_recov = <0x190>;
		battery,swelling_low_temp_block = <0x64>;
		battery,swelling_low_temp_recov = <0x96>;
		battery,swelling_chg_current = <0x60e>;
		battery,swelling_drop_float_voltage = <0x1068>;
		battery,swelling_high_rechg_voltage = <0x1022>;
		battery,swelling_low_rechg_voltage = <0xfbe>;
		battery,swelling_block_time = <0x258>;
		battery,chg_float_voltage = <0x10f2>;
		charger,vbus_ctrl_gpio = <0x35 0x40 0x00>;
		battery,input_current_limit = <0x3e8 0x1cc 0x1cc 0x3e8 0x1cc 0x3e8 0x3e8 0x1cc 0x1cc 0x3e8 0x3e8 0x3e8 0x3e8 0x1cc 0x3e8 0x12c 0x3e8 0x3e8 0x12c 0x3e8 0x3e8 0x1cc 0x1cc>;
		battery,fast_charging_current = <0x60e 0x00 0x3cf 0x60e 0x1f4 0x60e 0x60e 0x60e 0x00 0x60e 0x60e 0x60e 0x60e 0xffffffff 0x60e 0x60e 0x60e 0x60e 0x60e 0x60e 0x60e 0x00 0x00>;
		battery,full_check_current_1st = <0xaf 0x00 0xaf 0xaf 0xaf 0xaf 0xaf 0xaf 0x00 0xaf 0xaf 0xaf 0xaf 0x00 0xaf 0xaf 0xaf 0xaf 0xaf 0xaf 0xaf 0x00 0x00>;
		battery,full_check_current_2nd = <0x64 0x00 0x64 0x64 0x64 0x64 0x64 0x64 0x00 0x64 0x64 0x64 0x64 0x00 0x64 0x64 0x64 0x64 0x64 0x64 0x64 0x00 0x00>;
	};

	cpus {
		#address-cells = <0x01>;
		#size-cells = <0x00>;

		cpu@f00 {
			device_type = "cpu";
			compatible = "arm,cortex-a7";
			reg = <0xf00>;
		};

		cpu@f01 {
			device_type = "cpu";
			compatible = "arm,cortex-a7";
			reg = <0xf01>;
		};

		cpu@f02 {
			device_type = "cpu";
			compatible = "arm,cortex-a7";
			reg = <0xf02>;
		};

		cpu@f03 {
			device_type = "cpu";
			compatible = "arm,cortex-a7";
			reg = <0xf03>;
		};
	};

	interrupt-controller@12001000 {
		compatible = "arm,cortex-a15-gic\0arm,cortex-a9-gic";
		#interrupt-cells = <0x03>;
		#address-cells = <0x00>;
		interrupt-controller;
		reg = <0x12001000 0x1000 0x12002000 0x1000>;
		linux,phandle = <0x01>;
		phandle = <0x01>;
	};

	uart@70000000 {
		compatible = "sprd,serial";
		interrupts = <0x00 0x02 0x00>;
		reg = <0x70000000 0x1000>;
		clock-names = "clk_uart0";
		clocks = <0x36 0x3c>;
		sprdclk = <0x2dc6c00>;
		sprdwaketype = "BT_RTS_HIGH_WHEN_SLEEP";
	};

	uart@70100000 {
		compatible = "sprd,serial";
		interrupts = <0x00 0x03 0x00>;
		reg = <0x70100000 0x1000>;
		clock-names = "clk_uart1";
		clocks = <0x36 0x3d>;
		sprdclk = <0x18cba80>;
		sprdwaketype = "BT_RTS_HIGH_WHEN_SLEEP";
	};

	uart@70200000 {
		compatible = "sprd,serial";
		interrupts = <0x00 0x04 0x00>;
		reg = <0x70200000 0x1000>;
		clock-names = "clk_uart2";
		clocks = <0x36 0x3e>;
		sprdclk = <0x18cba80>;
		sprdwaketype = "BT_RTS_HIGH_WHEN_SLEEP";
	};

	uart@70300000 {
		compatible = "sprd,serial";
		interrupts = <0x00 0x05 0x00>;
		reg = <0x70300000 0x1000>;
		clock-names = "clk_uart3";
		clocks = <0x36 0x3f>;
		sprdclk = <0x18cba80>;
		sprdwaketype = "BT_RTS_HIGH_WHEN_SLEEP";
	};

	timer {
		compatible = "sprd,scx35-timer";
		reg = <0x40230000 0x1000 0x40050000 0x1000 0x40220000 0x1000 0x40320000 0x1000 0x40330000 0x1000>;
		interrupts = <0x00 0x76 0x00 0x00 0x1c 0x00 0x00 0x1d 0x00 0x00 0x77 0x00 0x00 0x79 0x00 0x00 0x1f 0x00>;
	};

	clockdevice {
		compatible = "sprd,scx35-clock";
		#clock-cells = <0x01>;
		linux,phandle = <0x36>;
		phandle = <0x36>;
	};

	gpio@40210000 {
		compatible = "sprd,d-eic-gpio";
		reg = <0x40210000 0x1000>;
		gpio-controller;
		interrupt-controller;
		#interrupt-cells = <0x02>;
		#gpio-cells = <0x02>;
		gpiobase = <0x120>;
		ngpios = <0x10>;
		interrupts = <0x00 0x25 0x00>;
	};

	gpio@40280000 {
		compatible = "sprd,d-gpio-gpio";
		reg = <0x40280000 0x1000>;
		gpio-controller;
		interrupt-controller;
		#interrupt-cells = <0x02>;
		#gpio-cells = <0x02>;
		gpiobase = <0x00>;
		ngpios = <0x100>;
		interrupts = <0x00 0x23 0x00>;
		linux,phandle = <0x35>;
		phandle = <0x35>;
	};

	pinctrl {
		compatible = "sprd,pinctrl";
		reg = <0x402a0000 0x1000>;
		pwr_domain = "vdd18\0vdd18\0vddsim0\0vddsim1\0vdd18\0vddsdcore\0vdd18";
		ctrl_desc = <0x10 0x00 0x01 0x10 0x01 0x01 0x10 0x02 0x01 0x10 0x03 0x01 0x10 0x04 0x01 0x10 0x05 0x01 0x10 0x06 0x01>;
	};

	sdios {
		#address-cells = <0x02>;
		#size-cells = <0x02>;
		ranges;

		sdio@20600000 {
			compatible = "sprd,sdhost-3.0";
			reg = <0x00 0x20600000 0x00 0x1000>;
			interrupts = <0x00 0x3c 0x00>;
			sprd,name = "sdio_emmc";
			signal_default_Voltage = <0x1b7740>;
			ocr_avail = <0x40000>;
			clocks = <0x37 0x1c>;
			base_clk = <0x16e36000>;
			caps = <0xc00f8d47>;
			caps2 = <0x202>;
			pm_caps = <0x04>;
			writeDelay = <0x34>;
			readPosDelay = <0x08>;
			readNegDelay = <0x08>;
		};

		sdio@20300000 {
			compatible = "sprd,sdhost-3.0";
			reg = <0x00 0x20300000 0x00 0x1000>;
			interrupts = <0x00 0x39 0x00>;
			sprd,name = "sdio_sd";
			detect_gpio = <0x90>;
			SD_Pwr_Name = "vddsdcore";
			signal_default_Voltage = <0x2dc6c0>;
			ocr_avail = <0x40000>;
			clocks = <0x38 0x1c>;
			base_clk = <0x16e36000>;
			caps = <0xc0000407>;
			caps2 = <0x200>;
			pm_caps = <0x04>;
			writeDelay = <0x03>;
			readPosDelay = <0x03>;
			readNegDelay = <0x03>;
		};

		sdio@20400000 {
			compatible = "sprd,sdhost-3.0";
			reg = <0x00 0x20400000 0x00 0x1000>;
			interrupts = <0x00 0x3a 0x00>;
			sprd,name = "sdio_wifi";
			ocr_avail = <0x360080>;
			clocks = <0x39 0x0e>;
			base_clk = <0x5b8d800>;
			caps = <0xc00fa407>;
			caps2 = <0x00>;
			pm_caps = <0x05>;
			writeDelay = <0x03>;
			readPosDelay = <0x03>;
			readNegDelay = <0x03>;
		};
	};

	adic {
		compatible = "sprd,adi";
		reg = <0x40030000 0x10000>;
	};

	adi_bus {
		compatible = "sprd,adi-bus";
		interrupts = <0x00 0x26 0x00>;
		reg = <0x40038000 0x1000>;
		interrupt-controller;
		sprd,irqnums = <0x0b>;
		#interrupt-cells = <0x02>;
		#address-cells = <0x01>;
		#size-cells = <0x01>;
		ranges = <0x40 0x40038040 0x40 0x80 0x40038080 0x80 0x100 0x40038100 0x80 0x480 0x40038480 0x80>;
		linux,phandle = <0x29>;
		phandle = <0x29>;

		watchdog@40 {
			compatible = "sprd,watchdog";
			reg = <0x40 0x40>;
			interrupts = <0x03 0x00>;
		};

		rtc@80 {
			compatible = "sprd,rtc";
			reg = <0x80 0x80>;
			interrupts = <0x02 0x00>;
		};

		gpio@100 {
			compatible = "sprd,a-eic-gpio";
			reg = <0x100 0x80>;
			gpio-controller;
			interrupt-controller;
			#interrupt-cells = <0x02>;
			#gpio-cells = <0x02>;
			gpiobase = <0x130>;
			ngpios = <0x10>;
			interrupt-parent = <0x29>;
			interrupts = <0x05 0x00>;
			linux,phandle = <0x34>;
			phandle = <0x34>;
		};

		gpio@480 {
			compatible = "sprd,a-gpio-gpio";
			reg = <0x480 0x80>;
			gpio-controller;
			interrupt-controller;
			#interrupt-cells = <0x02>;
			#gpio-cells = <0x02>;
			gpiobase = <0x100>;
			ngpios = <0x20>;
			interrupt-parent = <0x29>;
			interrupts = <0x01 0x00>;
		};

		keyboard_backlight {
			compatible = "sprd,keyboard-backlight";
		};

		headset_sprd_sc2723 {
			compatible = "sprd,headset_sprd_sc2723";
			gpio_switch = <0x00>;
			gpio_detect = <0x138>;
			gpio_button = <0x133>;
			irq_trigger_level_detect = <0x01>;
			irq_trigger_level_button = <0x01>;
			adc_threshold_gnd_average = <0x190>;
			adc_threshold_left_average = <0x1f4>;
			adc_threshold_3pole_detect = <0xcc5>;
			adc_threshold_4pole_detect = <0xcc6>;
			irq_threshold_buttont = <0x04>;
			voltage_headmicbias = <0x2dc6c0>;
			nbuttons = <0x04>;

			headset_buttons_media {
				adc_min = <0x00>;
				adc_max = <0x1f0>;
				code = <0xe2>;
				type = <0x00>;
			};

			headset_buttons_voc_assist {
				adc_min = <0x1f1>;
				adc_max = <0x2b7>;
				code = <0x246>;
				type = <0x00>;
			};

			headset_buttons_up {
				adc_min = <0x2b8>;
				adc_max = <0x4af>;
				code = <0x73>;
				type = <0x00>;
			};

			headset_buttons_down {
				adc_min = <0x4b0>;
				adc_max = <0xbb8>;
				code = <0x72>;
				type = <0x00>;
			};
		};
	};

	i2c_gpio@2 {
		compatible = "i2c-gpio";
		#address-cells = <0x01>;
		#size-cells = <0x00>;
		gpios = <0x35 0x9b 0x00 0x35 0x9a 0x00>;
		i2c-gpio,delay-us = <0x0a>;
		i2c-gpio,timeout-ms = <0x00>;

		sm5504@14 {
			compatible = "SiliconMitus,sm5504";
			reg = <0x14>;
			interrupt-parent = <0x35>;
			sm5504,irq-gpio = <0x35 0x34 0x00>;
		};
	};

	i2c_gpio@3 {
		compatible = "i2c-gpio";
		#address-cells = <0x01>;
		#size-cells = <0x00>;
		gpios = <0x35 0x35 0x00 0x35 0x37 0x00>;
		i2c-gpio,delay-us = <0x0a>;
		i2c-gpio,timeout-ms = <0x00>;
		status = "okay";

		coreriver@20 {
			compatible = "coreriver,coreriver-tkey";
			reg = <0x20>;
			interrupt-parent = <0x35>;
			coreriver,irq-gpio = <0x35 0x5a 0x00>;
			coreriver,sda-gpio = <0x35 0x35 0x00>;
			coreriver,scl-gpio = <0x35 0x37 0x00>;
			coreriver,vcc_en-gpio = <0x35 0x8c 0x00>;
			coreriver,fw_name = "coreriver/j3xlte.fw";
			coreriver,ext_fw_name = "/sdcard/tc350k_j3xlte.bin";
			coreriver,sensing_ch_num = <0x04>;
			coreriver,tsk_ic_num = <0x01>;
			coreriver,firm-up;
		};
	};

	i2c_gpio@4 {
		compatible = "i2c-gpio";
		#address-cells = <0x01>;
		#size-cells = <0x00>;
		gpios = <0x35 0x08 0x00 0x35 0x0a 0x00>;
		i2c-gpio,delay-us = <0x0a>;
		i2c-gpio,timeout-ms = <0x00>;

		cm36672p@60 {
			compatible = "cm36672p";
			reg = <0x60>;
			pinctrl-names = "default";
			interrupt-parent = <0x35>;
			interrupts = <0x5f 0x00>;
			cm36672p,vdd-supply = <0x3a>;
			cm36672p,leden_gpio = <0x35 0x8d 0x00>;
			cm36672p,irq_gpio = <0x35 0x5f 0x00>;
			cm36672p,default_hi_thd = <0x12>;
			cm36672p,default_low_thd = <0x0c>;
			cm36672p,cancel_hi_thd = <0x0a>;
			cm36672p,cancel_low_thd = <0x07>;
			cm36672p,ps_duty = <0x02>;
			cm36672p,ps_it = <0x04>;
			cm36672p,led_current = <0x03>;
			cm36672p,default_trim = <0x03>;
		};
	};

	sec_thermistor {
		compatible = "sec,thermistor";
	};

	gen-panel-backlight {
		compatible = "gen-panel-backlight";
		backlight-name = "panel";
		backlight-brt-range = <0x00 0x00 0x05 0x05 0x14 0x14 0x86 0x86 0xff 0xff 0xff 0xff>;
		backlight-brt-map = <0x00 0x00 0x04 0x04 0x06 0x06 0x07 0x07 0x08 0x08 0x09 0x09 0x0a 0x0a 0x0b 0x0b 0x0c 0x0c 0x0d 0x0d 0x0e 0x0e 0x0f 0x0f 0x10 0x10 0x11 0x11 0x12 0x13 0x13 0x14 0x14 0x15 0x15 0x16 0x16 0x18 0x17 0x19 0x18 0x1b 0x19 0x1d 0x1a 0x1e 0x1b 0x20 0x1c 0x22 0x1d 0x25 0x1e 0x27 0x1f 0x29 0x21 0x2c 0x23 0x2f 0x26 0x32 0x28 0x35 0x29 0x38 0x2e 0x3c 0x31 0x40 0x34 0x44 0x38 0x48 0x3b 0x4d 0x3f 0x52 0x43 0x57 0x47 0x5d 0x4c 0x62 0x50 0x69 0x56 0x6f 0x5b 0x77 0x61 0x7e 0x68 0x86 0x6e 0x8f 0x76 0x98 0x7d 0xa2 0x85 0xac 0x8e 0xb7 0x96 0xc3 0xa0 0xcf 0xaa 0xdc 0xb5 0xea 0xc1 0xf9 0xcd 0x109 0xda 0x11a 0xe6 0x12c 0xf2 0x13c 0xfe 0x14d 0xff 0x168 0xff 0x1f4>;
		gen-panel-bl-hbm-en;
		gen-panel-bl-tune-en;
		linux,phandle = <0x3c>;
		phandle = <0x3c>;
	};

	panel {
		compatible = "sprd,sprdfb-dsi-panel";
		pinctrl-names = "default";
		gen-panel = <0x3b>;
		gen-panel-backlight = <0x3c>;

		panel-ext-pin {
			panel-ext-pin-on-0 = <0x3d 0x00 0x0a 0x3e 0x01 0x0a>;
			panel-ext-pin-on = <0x3d 0x01 0x2710>;
			panel-ext-pin-off = <0x3d 0x00 0x0a 0x3e 0x00 0x0a>;

			panel-ext-pin-0 {
				pin-name = "panel_vci";
				pin-type = <0x01>;
				pin-supply = <0x3f>;
				linux,phandle = <0x3e>;
				phandle = <0x3e>;
			};

			panel-ext-pin-1 {
				pin-name = "panel_rst_n";
				pin-type = <0x00>;
				pin-gpio = <0x35 0x32 0x00>;
				linux,phandle = <0x3d>;
				phandle = <0x3d>;
			};
		};

		gen-panel {
			linux,phandle = <0x3b>;
			phandle = <0x3b>;

			gen-panel-s6e8aa5x01-video {
				gen-panel-manu = "SDC";
				gen-panel-name = "s6e8aa5";
				gen-panel-id = <0x400002 0x400003>;
				gen-panel-dev-id = <0x00>;
				gen-panel-type = <0x02>;
				gen-panel-refresh = <0x3c>;
				gen-panel-xres = <0x2d0>;
				gen-panel-yres = <0x500>;
				gen-panel-width = <0x3e>;
				gen-panel-height = <0x6a>;
				gen-panel-work-mode = <0x01>;
				gen-panel-direction = <0x00>;
				gen-panel-suspend-mode = <0x01>;
				gen-panel-bus-width = <0x18>;
				gen-panel-lanes = <0x04>;
				gen-panel-phy-feq = <0x7a120>;
				gen-panel-h-sync-pol = <0x00>;
				gen-panel-v-sync-pol = <0x00>;
				gen-panel-de-pol = <0x00>;
				gen-panel-te-pol = <0x00>;
				gen-panel-color-mode-pol = <0x01>;
				gen-panel-shut-down-pol = <0x01>;
				gen-panel-h-front-porch = <0x82>;
				gen-panel-h-back-porch = <0x5a>;
				gen-panel-h-sync-width = <0x28>;
				gen-panel-v-front-porch = <0x0e>;
				gen-panel-v-back-porch = <0x06>;
				gen-panel-v-sync-width = <0x04>;
				gen-panel-octa-tset-param-offset = <0x07>;
				gen-panel-octa-mps-param-offset = <0x00>;
				gen-panel-octa-elvss-param-offset = <0x01>;
				gen-panel-octa-elvss-temp-param-offset = <0x15>;
				gen-panel-octa-aid-param-offset = <0x00>;
				gen-panel-octa-hbm-gamma-param-offset = <0x01>;
				gen-panel-octa-product-reg = [c8];
				gen-panel-octa-product-gpara = <0x28>;
				gen-panel-octa-coordinate-reg = [d7];
				gen-panel-octa-coordinate-gpara = <0x03>;
				gen-panel-acl-always-on;
				gen-panel-pkt-dinfo-addr-offset = <0x00>;
				gen-panel-pkt-dinfo-addr-length = <0x01>;
				gen-panel-pkt-dinfo-data-offset = <0x01>;
				gen-panel-pkt-dinfo-data-length = <0x01>;
				gen-panel-post-enable-cmds = [05 00 00 16 00 01 11];
				gen-panel-post-enable-1-cmds = [39 00 00 00 00 03 f0 5a 5a 39 00 00 00 00 04 c0 d8 d8 40 39 00 00 00 00 08 b8 38 00 00 60 44 00 a8 39 00 00 78 00 03 f0 a5 a5 05 00 00 10 00 01 29];
				gen-panel-disable-cmds = [05 00 00 14 00 01 28 05 00 00 78 00 01 10];
				gen-panel-nv-read-enable-cmds = [39 00 00 00 00 03 f0 5a 5a];
				gen-panel-nv-read-disable-cmds = [39 00 00 00 00 03 f0 a5 a5];
				gen-panel-acl-on-cmds = <0x15000000 0x25502 0x15000000 0x2b550>;
				gen-panel-acl-off-cmds = <0x15000000 0x25500 0x15000000 0x2b540>;
				gen-panel-hbm-on-cmds = [39 00 00 00 00 03 b6 bc 0f 15 00 00 00 00 02 b5 50 15 00 00 00 00 02 53 c0 39 00 00 00 00 23 b4 0b 01 27 01 21 01 27 80 80 80 80 80 80 80 80 80 80 80 80 80 80 80 80 80 80 80 80 80 80 80 80 00 00 00 15 00 00 00 00 02 55 02];
				gen-panel-hbm-off-cmds = <0x15000000 0x25300>;
				gen-panel-tset-cmds = [39 00 00 00 00 09 b8 19 00 00 60 44 00 a8 19];
				gen-panel-elvss-cmds = [39 00 00 00 00 17 b6 bc 0f 00 00 00 00 00 00 00 00 00 80 00 0a aa a2 12 03 33 21 10 07];
				gen-panel-aid-cmds = <0x39000000 0x6b240 0x28000a>;
				gen-panel-octa-vregout = <0x1733333>;
				gen-panel-candela-table = <0x05 0x06 0x07 0x08 0x09 0x0a 0x0b 0x0c 0x0d 0x0e 0x0f 0x10 0x11 0x13 0x14 0x15 0x16 0x18 0x19 0x1b 0x1d 0x1e 0x20 0x22 0x25 0x27 0x29 0x2c 0x2f 0x32 0x35 0x38 0x3c 0x40 0x44 0x48 0x4d 0x52 0x57 0x5d 0x62 0x69 0x6f 0x77 0x7e 0x86 0x8f 0x98 0xa2 0xac 0xb7 0xc3 0xcf 0xdc 0xea 0xf9 0x109 0x11a 0x12c 0x13c 0x14d 0x168>;
				gen-panel-acl-table = <0x02 0x02 0x02 0x02 0x02 0x02 0x02 0x02 0x02 0x02 0x02 0x02 0x02 0x02 0x02 0x02 0x02 0x02 0x02 0x02 0x02 0x02 0x02 0x02 0x02 0x02 0x02 0x02 0x02 0x02 0x02 0x02 0x02 0x02 0x02 0x02 0x02 0x02 0x02 0x02 0x02 0x02 0x02 0x02 0x02 0x02 0x02 0x02 0x02 0x02 0x02 0x02 0x02 0x02 0x02 0x02 0x02 0x02 0x02 0x02 0x02 0x02>;
				gen-panel-aid-table = <0x4ee 0x4e1 0x4d4 0x4cf 0x4c2 0x4b4 0x4af 0x4a3 0x496 0x491 0x482 0x475 0x470 0x454 0x450 0x442 0x433 0x41e 0x410 0x3f2 0x3de 0x3c6 0x3b1 0x395 0x373 0x35f 0x343 0x320 0x2fe 0x2df 0x2b2 0x290 0x25e 0x230 0x1f4 0x1f4 0x1f4 0x1f4 0x1f4 0x1f4 0x1f4 0x1f4 0x1f4 0x1f4 0x1bf 0x182 0x140 0x100 0xb2 0x62 0x0f 0x0f 0x0f 0x0f 0x0f 0x0f 0x0f 0x0f 0x0f 0x0f 0x0f 0x0f>;
				gen-panel-mps-table = <0xac 0xac 0xac 0xac 0xac 0xac 0xac 0xac 0xac 0xac 0xac 0xac 0xac 0xac 0xac 0xac 0xac 0xac 0xac 0xac 0xac 0xac 0xac 0xac 0xac 0xac 0xbc 0xbc 0xbc 0xbc 0xbc 0xbc 0xbc 0xbc 0xbc 0xbc 0xbc 0xbc 0xbc 0xbc 0xbc 0xbc 0xbc 0xbc 0xbc 0xbc 0xbc 0xbc 0xbc 0xbc 0xbc 0xbc 0xbc 0xbc 0xbc 0xbc 0xbc 0xbc 0xbc 0xbc 0xbc 0xbc>;
				gen-panel-elvss-table = <0x0f 0x0f 0x0f 0x0f 0x0f 0x0f 0x0f 0x0f 0x0f 0x0f 0x0f 0x0f 0x0f 0x0f 0x0f 0x11 0x14 0x17 0x19 0x1b 0x1d 0x1f 0x1f 0x1f 0x1f 0x1f 0x1f 0x1f 0x1f 0x1f 0x1f 0x1f 0x1f 0x1f 0x1f 0x1f 0x1f 0x1f 0x1f 0x1f 0x1f 0x1f 0x1e 0x1e 0x1e 0x1e 0x1d 0x1d 0x1d 0x1d 0x1c 0x1b 0x1a 0x18 0x18 0x17 0x16 0x14 0x13 0x12 0x10 0x0f>;
				gen-panel-elvss-temperature-table = <0x05 0x05 0x05 0x05 0x05 0x05 0x05 0x05 0x05 0x05 0x05 0x05 0x05 0x05 0x05 0x07 0x07 0x07 0x07 0x07 0x07 0x00 0x00 0x00 0x00 0x00 0x00 0x00 0x00 0x00 0x00 0x00 0x00 0x00 0x00 0x00 0x00 0x00 0x00 0x00 0x00 0x00 0x00 0x00 0x00 0x00 0x00 0x00 0x00 0x00 0x00 0x00 0x00 0x00 0x00 0x00 0x00 0x00 0x00 0x00 0x00 0x00 0x0f 0x0f 0x0f 0x0f 0x0f 0x0f 0x0f 0x0f 0x0f 0x0f 0x0f 0x0f 0x0f 0x0f 0x0f 0x0f 0x0e 0x0d 0x0c 0x0b 0x0a 0x00 0x00 0x00 0x00 0x00 0x00 0x00 0x00 0x00 0x00 0x00 0x00 0x00 0x00 0x00 0x00 0x00 0x00 0x00 0x00 0x00 0x00 0x00 0x00 0x00 0x00 0x00 0x00 0x00 0x00 0x00 0x00 0x00 0x00 0x00 0x00 0x00 0x00 0x00 0x00 0x00 0x13 0x13 0x13 0x13 0x13 0x13 0x13 0x13 0x13 0x13 0x13 0x13 0x13 0x13 0x13 0x13 0x12 0x10 0x0e 0x0c 0x0a 0x00 0x00 0x00 0x00 0x00 0x00 0x00 0x00 0x00 0x00 0x00 0x00 0x00 0x00 0x00 0x00 0x00 0x00 0x00 0x00 0x00 0x00 0x00 0x00 0x00 0x00 0x00 0x00 0x00 0x00 0x00 0x00 0x00 0x00 0x00 0x00 0x00 0x00 0x00 0x00 0x00>;
				gen-panel-base-lux-table = <0x71 0x71 0x71 0x71 0x71 0x71 0x71 0x71 0x71 0x71 0x71 0x71 0x71 0x71 0x71 0x71 0x71 0x71 0x71 0x71 0x71 0x71 0x71 0x71 0x71 0x71 0x71 0x71 0x71 0x71 0x71 0x71 0x71 0x71 0x71 0x76 0x7f 0x87 0x8e 0x97 0xa0 0xac 0xb4 0xc0 0xc0 0xc0 0xc0 0xc0 0xc0 0xc0 0xc0 0xcc 0xd7 0xe4 0xf0 0xff 0x10f 0x11e 0x12f 0x13e 0x150 0x168>;
				gen-panel-gamma-curve-table = <0xc8 0xc8 0xc8 0xc8 0xc8 0xc8 0xc8 0xc8 0xc8 0xc8 0xc8 0xc8 0xc8 0xc8 0xc8 0xc8 0xc8 0xc8 0xc8 0xc8 0xc8 0xc8 0xc8 0xc8 0xc8 0xc8 0xc8 0xc8 0xc8 0xc8 0xc8 0xc8 0xc8 0xc8 0xc8 0xc8 0xc8 0xc8 0xc8 0xc8 0xc8 0xc8 0xc8 0xc8 0xc8 0xc8 0xc8 0xc8 0xc8 0xc8 0xc8 0xc8 0xc8 0xc8 0xc8 0xc8 0xc8 0xc8 0xc8 0xc8 0xc8 0xc8>;
				gen-panel-candela-compensation-table = <0x00 0x03 0x02 0x02 0x03 0x03 0x07 0x09 0x05 0x00 0x02 0x01 0x02 0x03 0x03 0x06 0x09 0x05 0x00 0x03 0x02 0x02 0x03 0x03 0x06 0x09 0x05 0x00 0x03 0x02 0x01 0x02 0x03 0x05 0x08 0x05 0x00 0x03 0x02 0x01 0x02 0x02 0x05 0x07 0x05 0x00 0x02 0x01 0x01 0x02 0x02 0x05 0x07 0x05 0x00 0x02 0x01 0x01 0x01 0x02 0x04 0x07 0x05 0x00 0x03 0x02 0x01 0x02 0x02 0x04 0x06 0x05 0x00 0x02 0x01 0x01 0x01 0x02 0x04 0x06 0x05 0x00 0x03 0x02 0x01 0x02 0x02 0x04 0x05 0x05 0x00 0x02 0x01 0x01 0x01 0x02 0x03 0x05 0x05 0x00 0x02 0x01 0x01 0x01 0x01 0x03 0x04 0x05 0x00 0x03 0x02 0x01 0x01 0x01 0x03 0x04 0x05 0x00 0x02 0x01 0x01 0x01 0x01 0x03 0x04 0x05 0x00 0x03 0x02 0x01 0x01 0x01 0x03 0x04 0x05 0x00 0x03 0x02 0x01 0x01 0x01 0x03 0x04 0x05 0x00 0x03 0x02 0x01 0x01 0x02 0x03 0x04 0x05 0x00 0x03 0x02 0x01 0x02 0x02 0x03 0x04 0x05 0x00 0x03 0x02 0x02 0x02 0x02 0x04 0x05 0x05 0x00 0x03 0x03 0x02 0x02 0x02 0x04 0x05 0x05 0x00 0x03 0x03 0x02 0x02 0x02 0x04 0x05 0x05 0x00 0x03 0x03 0x02 0x02 0x02 0x04 0x05 0x05 0x00 0x03 0x03 0x02 0x02 0x02 0x04 0x05 0x05 0x00 0x03 0x03 0x02 0x02 0x02 0x04 0x05 0x05 0x00 0x03 0x03 0x02 0x02 0x02 0x04 0x04 0x05 0x00 0x03 0x03 0x02 0x02 0x02 0x03 0x04 0x05 0x00 0x03 0x03 0x02 0x02 0x02 0x03 0x04 0x05 0x00 0x03 0x03 0x02 0x02 0x02 0x03 0x04 0x04 0x00 0x03 0x03 0x02 0x02 0x02 0x03 0x03 0x04 0x00 0x03 0x03 0x02 0x02 0x02 0x03 0x03 0x04 0x00 0x03 0x03 0x02 0x02 0x02 0x02 0x03 0x04 0x00 0x03 0x03 0x02 0x02 0x02 0x02 0x03 0x04 0x00 0x03 0x03 0x02 0x02 0x02 0x02 0x03 0x03 0x00 0x03 0x03 0x02 0x02 0x02 0x02 0x03 0x03 0x00 0x03 0x03 0x02 0x02 0x02 0x02 0x03 0x03 0x00 0x03 0x03 0x02 0x02 0x02 0x02 0x03 0x03 0x00 0x03 0x03 0x02 0x02 0x02 0x02 0x02 0x03 0x00 0x03 0x03 0x03 0x02 0x02 0x02 0x02 0x03 0x00 0x03 0x03 0x04 0x02 0x02 0x02 0x02 0x03 0x00 0x03 0x03 0x04 0x02 0x02 0x02 0x02 0x03 0x00 0x03 0x03 0x04 0x02 0x02 0x02 0x02 0x03 0x00 0x02 0x03 0x04 0x03 0x02 0x02 0x02 0x03 0x00 0x02 0x03 0x04 0x03 0x02 0x02 0x02 0x03 0x00 0x02 0x03 0x04 0x03 0x02 0x02 0x02 0x03 0x00 0x02 0x03 0x04 0x03 0x02 0x02 0x02 0x03 0x00 0x02 0x03 0x04 0x03 0x02 0x02 0x02 0x03 0x00 0x02 0x03 0x04 0x03 0x02 0x02 0x02 0x02 0x00 0x02 0x03 0x04 0x02 0x02 0x02 0x02 0x02 0x00 0x02 0x03 0x03 0x02 0x02 0x02 0x02 0x02 0x00 0x02 0x03 0x03 0x02 0x02 0x02 0x02 0x02 0x00 0x01 0x03 0x03 0x02 0x02 0x02 0x02 0x02 0x00 0x01 0x03 0x03 0x02 0x02 0x02 0x02 0x02 0x00 0x01 0x03 0x03 0x02 0x02 0x02 0x02 0x02 0x00 0x01 0x03 0x03 0x02 0x02 0x02 0x01 0x02 0x00 0x01 0x03 0x03 0x02 0x02 0x02 0x01 0x02 0x00 0x01 0x03 0x03 0x02 0x02 0x02 0x01 0x02 0x00 0x01 0x03 0x03 0x02 0x02 0x02 0x00 0x01 0x00 0x01 0x02 0x02 0x02 0x02 0x01 0x00 0x01 0x00 0x01 0x01 0x02 0x02 0x02 0x01 0x00 0x00 0x00 0x00 0x01 0x02 0x02 0x01 0x01 0x00 0x00 0x00 0x00 0x01 0x01 0x02 0x01 0x01 0x00 0x00 0x00 0x00 0x00 0x00 0x00 0x00 0x00 0x00 0x00>;
				gen-panel-rgb-compensation-table = <0x02 0x00 0x01 0x00 0x00 0x01 0xffffffff 0x00 0x02 0xfffffffd 0x00 0x00 0xfffffffb 0x00 0x04 0xfffffffa 0x00 0xfffffffd 0xfffffff2 0x00 0xfffffffe 0x00 0x00 0x01 0x02 0x00 0x01 0x00 0x00 0x01 0xffffffff 0x00 0x01 0xfffffffe 0x00 0x00 0xfffffffc 0x00 0x04 0xfffffffa 0x00 0xfffffffd 0xfffffff3 0x00 0xfffffffc 0xfffffffd 0x00 0x01 0x02 0x00 0x01 0x00 0x00 0x01 0x00 0x00 0x02 0xfffffffd 0x00 0x00 0xfffffffc 0x00 0x03 0xfffffffb 0x00 0xfffffffd 0xfffffff3 0x00 0xfffffffd 0xfffffffa 0x00 0x00 0x02 0x00 0x01 0x00 0x00 0x01 0x00 0x00 0x02 0xffffffff 0x00 0x01 0xfffffffc 0x00 0x03 0xfffffffb 0x00 0xfffffffc 0xfffffff4 0x00 0xfffffffc 0xfffffff8 0x00 0x00 0x02 0x00 0x01 0x00 0x00 0x01 0x00 0x00 0x02 0xffffffff 0x00 0x01 0xfffffffd 0x00 0x03 0xfffffffb 0x00 0xfffffffb 0xfffffff6 0x00 0xfffffffe 0xfffffff6 0x00 0x01 0x02 0x00 0x01 0x00 0x00 0x01 0xffffffff 0x00 0x01 0x00 0x00 0x01 0xfffffffc 0x00 0x02 0xfffffffc 0x00 0xfffffffd 0xfffffff8 0x00 0xfffffffe 0xfffffff4 0x00 0xffffffff 0x02 0x00 0x01 0x00 0x00 0x01 0xffffffff 0x00 0x01 0x00 0x00 0x01 0xfffffffd 0x00 0x02 0xfffffffc 0x00 0xfffffffd 0xfffffff7 0x00 0xfffffffd 0xfffffff3 0x00 0xffffffff 0x02 0x00 0x01 0x00 0x00 0x01 0xffffffff 0x00 0x01 0xffffffff 0x00 0x01 0xfffffffe 0x00 0x03 0xfffffffd 0x00 0xfffffffb 0xfffffff7 0x00 0xfffffffe 0xfffffff3 0x00 0xffffffff 0x02 0x00 0x01 0x00 0x00 0x01 0x00 0x00 0x01 0xffffffff 0x00 0x01 0xfffffffd 0x00 0x02 0xfffffffd 0x00 0xfffffffb 0xfffffff9 0x00 0xffffffff 0xfffffff5 0x00 0xffffffff 0x02 0x00 0x01 0x00 0x00 0x01 0x00 0x00 0x02 0xfffffffe 0x00 0x00 0xfffffffe 0x00 0x03 0xfffffffe 0x00 0xfffffffb 0xfffffffb 0x00 0xfffffffe 0xfffffff5 0x00 0xffffffff 0x02 0x00 0x01 0x00 0x00 0x01 0x00 0x00 0x01 0xfffffffe 0x00 0x00 0xfffffffe 0x00 0x03 0xffffffff 0x00 0xfffffffc 0xfffffff9 0x00 0xfffffffd 0xfffffff5 0x00 0xfffffffe 0x02 0x00 0x01 0x00 0x00 0x01 0x00 0x00 0x01 0xfffffffe 0x00 0x00 0xffffffff 0x00 0x03 0xffffffff 0x00 0xfffffffc 0xfffffffb 0x00 0xfffffffd 0xfffffff3 0x00 0xfffffffe 0x02 0x00 0x01 0x00 0x00 0x01 0x00 0x00 0x02 0xfffffffe 0x00 0x00 0xfffffffe 0x00 0x02 0xffffffff 0x00 0xfffffffc 0xfffffffb 0x00 0xfffffffd 0xfffffff5 0x00 0x00 0x02 0x00 0x01 0xffffffff 0x00 0x00 0x00 0x00 0x02 0x00 0x00 0x01 0xfffffffe 0x00 0x02 0xffffffff 0x00 0xfffffffc 0xfffffffb 0x00 0xfffffffc 0xfffffff7 0x00 0x01 0x02 0x00 0x01 0xffffffff 0x00 0x00 0x00 0x00 0x02 0x00 0x00 0x01 0xfffffffe 0x00 0x02 0xffffffff 0x00 0xfffffffc 0xfffffffb 0x00 0xfffffffd 0xfffffff8 0x00 0x02 0x02 0x00 0x01 0xffffffff 0x00 0x00 0x00 0x00 0x02 0x00 0x00 0x01 0xfffffffe 0x00 0x02 0x00 0x00 0xfffffffc 0xfffffffa 0x00 0xfffffffb 0xfffffff9 0x00 0x00 0x02 0x00 0x01 0xffffffff 0x00 0x00 0x00 0x00 0x02 0x00 0x00 0x01 0xfffffffe 0x00 0x02 0x00 0x00 0xfffffffc 0xfffffffa 0x00 0xfffffffc 0xfffffff9 0x01 0xfffffffd 0x02 0x00 0x01 0xffffffff 0x00 0x00 0x00 0x00 0x02 0x00 0x00 0x01 0xfffffffe 0x00 0x02 0x00 0x00 0xfffffffc 0xfffffffa 0x00 0xfffffffa 0xfffffff9 0x01 0xfffffffd 0x02 0x00 0x01 0xffffffff 0x00 0x00 0x00 0x00 0x02 0x00 0x00 0x01 0xfffffffd 0x00 0x01 0x00 0x00 0xfffffffb 0xfffffffb 0x00 0xfffffffb 0xfffffff7 0x00 0xfffffffc 0x02 0x00 0x01 0xffffffff 0x00 0x01 0x00 0x00 0x02 0xffffffff 0x00 0x00 0xfffffffe 0x00 0x01 0x00 0x00 0xfffffffb 0xfffffffd 0x00 0xfffffffb 0xfffffff7 0x00 0xfffffffb 0x02 0x00 0x01 0xffffffff 0x00 0x01 0x00 0x00 0x02 0xffffffff 0x00 0x00 0xfffffffe 0x00 0x01 0x00 0x00 0xfffffffb 0xfffffffd 0x00 0xfffffffb 0xfffffff7 0x00 0xfffffffb 0x02 0x00 0x01 0xffffffff 0x00 0x01 0x00 0x00 0x02 0xffffffff 0x00 0x00 0xfffffffe 0x00 0x01 0x00 0x00 0xfffffffa 0xfffffffc 0x00 0xfffffffb 0xfffffff7 0x00 0xfffffff9 0x02 0x00 0x00 0xffffffff 0x00 0x01 0x00 0x00 0x02 0xffffffff 0x00 0x00 0xfffffffe 0x00 0x01 0x01 0x00 0xfffffffa 0xfffffffd 0x00 0xfffffffb 0xfffffff7 0x00 0xfffffffa 0x02 0x00 0x00 0xffffffff 0x00 0x01 0x00 0x00 0x02 0xffffffff 0x00 0x00 0xffffffff 0x00 0x01 0x01 0x00 0xfffffffa 0xfffffffd 0x00 0xfffffffc 0xfffffff7 0x00 0xfffffffa 0x02 0x00 0x00 0xffffffff 0x00 0x01 0x00 0x00 0x02 0xffffffff 0x00 0x00 0xffffffff 0x00 0x01 0x01 0x00 0xfffffffa 0xfffffffe 0x00 0xfffffffc 0xfffffff7 0x00 0xfffffff9 0x02 0x00 0x00 0xffffffff 0x00 0x01 0x00 0x00 0x02 0xffffffff 0x00 0x00 0xffffffff 0x00 0x01 0x01 0x00 0xfffffffa 0xfffffffe 0x00 0xfffffffb 0xfffffff8 0x00 0xfffffffc 0x02 0x00 0x00 0xffffffff 0x00 0x01 0xffffffff 0x00 0x02 0xffffffff 0x00 0x00 0xffffffff 0x00 0x01 0x02 0x00 0xfffffffa 0xffffffff 0x00 0xfffffffc 0xfffffff8 0x00 0xfffffffd 0x02 0x00 0x00 0xffffffff 0x00 0x01 0xffffffff 0x00 0x02 0xffffffff 0x00 0x00 0xffffffff 0x00 0x01 0x02 0x00 0xfffffffa 0xffffffff 0x00 0xfffffffc 0xfffffff9 0x00 0xfffffffe 0x02 0x00 0x00 0xffffffff 0x00 0x01 0xffffffff 0x00 0x02 0xffffffff 0x00 0x00 0xffffffff 0x00 0x01 0x02 0x00 0xfffffffa 0xffffffff 0x00 0xfffffffc 0xfffffffa 0x00 0xfffffffd 0x02 0x00 0x00 0xffffffff 0x00 0x01 0xffffffff 0x00 0x02 0xffffffff 0x00 0x00 0xffffffff 0x00 0x01 0x03 0x00 0xfffffffb 0xfffffffe 0x00 0xfffffffc 0xfffffffb 0x00 0xffffffff 0x02 0x00 0x00 0xffffffff 0x00 0x01 0xffffffff 0x00 0x02 0xffffffff 0x00 0x00 0xffffffff 0x00 0x01 0x03 0x00 0xfffffffb 0xffffffff 0x00 0xfffffffc 0xfffffffb 0x00 0x00 0x02 0x00 0x00 0xffffffff 0x00 0x01 0xffffffff 0x00 0x02 0xffffffff 0x00 0x00 0xffffffff 0x00 0x01 0x03 0x00 0xfffffffb 0xffffffff 0x00 0xfffffffc 0xfffffffb 0x00 0x01 0x02 0x00 0x00 0xffffffff 0x00 0x01 0xffffffff 0x00 0x02 0xffffffff 0x00 0x00 0xffffffff 0x00 0x01 0x03 0x00 0xfffffffb 0x00 0x00 0xfffffffc 0xfffffffb 0x00 0x03 0x02 0x00 0x00 0xffffffff 0x00 0x01 0xffffffff 0x00 0x02 0xffffffff 0x00 0x00 0xffffffff 0x00 0x01 0x03 0x00 0xfffffffb 0x00 0x00 0xfffffffc 0xfffffffb 0x00 0x04 0x01 0x00 0x00 0xffffffff 0x00 0x00 0xffffffff 0x00 0x01 0xffffffff 0x00 0x00 0x00 0x00 0x02 0x03 0x00 0xfffffffb 0x00 0x00 0xfffffffc 0xfffffffa 0x00 0x00 0x01 0x00 0x00 0xffffffff 0x00 0x00 0xffffffff 0x00 0x01 0xffffffff 0x00 0x00 0x00 0x00 0x02 0x02 0x00 0xfffffffc 0x00 0x00 0xfffffffc 0xfffffffb 0x00 0x00 0x01 0x00 0x00 0xffffffff 0x00 0x00 0xffffffff 0x00 0x01 0xffffffff 0x00 0x00 0x00 0x00 0x02 0x01 0x00 0xfffffffb 0x00 0x00 0xfffffffd 0xfffffffd 0x00 0x00 0x01 0x00 0x00 0xffffffff 0x00 0x00 0xffffffff 0x00 0x01 0xffffffff 0x00 0x00 0x00 0x00 0x02 0x01 0x00 0xfffffffc 0x00 0x00 0xfffffffd 0xfffffffb 0x00 0x00 0x01 0x00 0x00 0xffffffff 0x00 0x00 0xffffffff 0x00 0x01 0xffffffff 0x00 0xffffffff 0x00 0x00 0x03 0x01 0x00 0xfffffffc 0x00 0x00 0xfffffffc 0xfffffffd 0x00 0x01 0x01 0x00 0x00 0xffffffff 0x00 0x00 0xffffffff 0x00 0x01 0xffffffff 0x00 0xffffffff 0xffffffff 0x00 0x02 0x03 0x00 0xfffffffc 0x00 0x00 0xfffffffc 0xfffffffd 0x00 0x00 0x01 0x00 0x00 0xffffffff 0x00 0x00 0xffffffff 0x00 0x01 0xffffffff 0x00 0xffffffff 0x00 0x00 0x02 0x03 0x00 0xfffffffd 0x00 0x00 0xfffffffc 0xfffffffd 0x00 0x00 0x01 0x00 0x00 0xffffffff 0x00 0x00 0x00 0x00 0x01 0xffffffff 0x00 0xffffffff 0x00 0x00 0x02 0x01 0x00 0xfffffffc 0x00 0x00 0xfffffffc 0xfffffffc 0x00 0x00 0x01 0x00 0x00 0x00 0x00 0x00 0x00 0x00 0x01 0xffffffff 0x00 0xffffffff 0x00 0x00 0x02 0x01 0x00 0xfffffffd 0x00 0x00 0xfffffffc 0xfffffffd 0x00 0xffffffff 0x00 0x00 0x00 0x01 0x00 0xffffffff 0xffffffff 0x00 0x01 0xffffffff 0x00 0x00 0x00 0x00 0x00 0x00 0x00 0xfffffffd 0x01 0x00 0xffffffff 0xfffffffe 0x00 0xffffffff 0x00 0x00 0x00 0x01 0x00 0xffffffff 0xffffffff 0x00 0x00 0xffffffff 0x00 0x00 0xffffffff 0x00 0x01 0x01 0x00 0xfffffffd 0x01 0x00 0xffffffff 0xffffffff 0x00 0x00 0x00 0x00 0x00 0x01 0x00 0xffffffff 0xffffffff 0x00 0x00 0xffffffff 0x00 0x00 0xffffffff 0x00 0x01 0x01 0x00 0xfffffffd 0x01 0x00 0xffffffff 0xffffffff 0x00 0x00 0x00 0x00 0x00 0x01 0x00 0xffffffff 0xffffffff 0x00 0x00 0xffffffff 0x00 0x00 0xffffffff 0x00 0x01 0x01 0x00 0xfffffffd 0x01 0x00 0xffffffff 0x00 0x00 0x01 0x00 0x00 0x00 0x01 0x00 0xffffffff 0xffffffff 0x00 0x00 0xffffffff 0x00 0x00 0xffffffff 0x00 0x01 0x01 0x00 0xfffffffd 0x01 0x00 0xffffffff 0x01 0x00 0x01 0x00 0x00 0x00 0x01 0x00 0xffffffff 0xffffffff 0x00 0x00 0x00 0x00 0x01 0xffffffff 0x00 0x01 0x01 0x00 0xfffffffd 0x00 0x00 0xfffffffe 0x00 0x00 0x01 0x00 0x00 0x00 0x01 0x00 0xffffffff 0xffffffff 0x00 0x00 0x00 0x00 0x01 0xffffffff 0x00 0x01 0x01 0x00 0xfffffffd 0x00 0x00 0xfffffffe 0x00 0x00 0x01 0x00 0x00 0x00 0x00 0x00 0x00 0x00 0x00 0x00 0x00 0x00 0x00 0x00 0x00 0x00 0x00 0x00 0x00 0x00 0x00 0x00 0x00 0x00 0x00 0x00 0x00 0x00 0x00 0x00 0x00 0x00 0x00 0x00 0x00 0x00 0x00 0x00 0x00 0x00 0x00 0x00 0x00 0x00 0x00 0x00 0x00 0x00 0x00 0x00 0x00 0x00 0x00 0x00 0x00 0x00 0x00 0x00 0x00 0x00 0x00 0x00 0x00 0x00 0x00 0x00 0x00 0x00 0x00 0x00 0x00 0x00 0x00 0x00 0x00 0x00 0x00 0x00 0x00 0x00 0x00 0x00 0x00 0x00 0x00 0x00 0x00 0x00 0x00 0x00 0x00 0x00 0x00 0x00 0x00 0x00 0x00 0x00 0x00 0x00 0x00 0x00 0x00 0x00 0x00 0x00 0x00 0x00 0x00 0x00 0x00 0x00 0x00 0x00 0x00 0x00 0x00 0x00 0x00 0x00 0x00 0x00 0x00 0x00 0x00 0x00 0x00 0x00 0x00 0x00 0x00 0x00 0x00 0x00 0x00 0x00 0x00 0x00 0x00 0x00 0x00 0x00 0x00 0x00 0x00 0x00 0x00 0x00 0x00 0x00 0x00 0x00 0x00 0x00 0x00 0x00 0x00 0x00 0x00 0x00 0x00 0x00 0x00 0x00 0x00 0x00 0x00 0x00 0x00 0x00 0x00 0x00 0x00 0x00 0x00 0x00 0x00 0x00 0x00 0x00 0x00 0x00 0x00 0x00 0x00 0x00 0x00 0x00 0x00 0x00 0x00 0x00 0x00 0x00 0x00 0x00 0x00 0x00 0x00 0x00 0x00 0x00 0x00 0x00 0x00 0x00 0x00 0x00 0x00 0x00 0x00 0x00 0x00 0x00 0x00 0x00 0x00 0x00 0x00 0x00 0x00 0x00 0x00 0x00 0x00 0x00 0x00 0x00 0x00 0x00 0x00 0x00 0x00 0x00 0x00 0x00 0x00 0x00 0x00 0x00 0x00 0x00 0x00 0x00 0x00 0x00 0x00 0x00 0x00 0x00 0x00 0x00 0x00 0x00 0x00 0x00 0x00 0x00 0x00 0x00 0x00 0x00 0x00 0x00 0x00 0x00 0x00 0x00 0x00 0x00 0x00 0x00 0x00 0x00 0x00 0x00 0x00 0x00 0x00 0x00 0x00 0x00 0x00 0x00 0x00 0x00 0x00 0x00 0x00>;
				gen-panel-gamma-cmds = <0x39000000 0x22ca01 0x10001 0x808080 0x80808080 0x80808080 0x80808080 0x80808080 0x80808080 0x80000000>;
				gen-panel-gamma-update-cmds = <0x15000005 0x2f703>;
				gen-panel-read-hbm = [c8 21 06 c8 48 0f];
				gen-panel-read-mtp = [c8 00 21];
				gen-panel-read-id = [da 00 01 db 00 01 dc 00 01];
				gen-panel-read-status-reg = [0a];
				gen-panel-read-status-ok = [9a];
				status = "okay";
				gen-panel-mdnie-color-adjustment-mode-reg = [ec];
				gen-panel-mdnie-color-adjustment-mode-offset = <0x6a>;
				gen-panel-mdnie-negative-mode-cmds = [39 00 00 00 00 83 ec 00 00 00 00 00 00 00 00 00 00 00 00 00 00 00 00 00 00 ff 00 00 07 ff 07 ff 01 00 00 20 00 20 00 20 00 20 00 20 00 20 00 20 00 20 00 20 00 20 00 20 00 20 00 20 00 20 00 20 00 20 00 20 00 20 00 20 00 20 00 20 00 20 00 20 00 ff 00 67 a9 0c 0c 0c 0c 00 aa ab 00 aa ab 00 aa ab 00 aa ab ff 00 00 ff ff 00 ff 00 ff ff ff ff ff 00 00 ff 00 ff 00 ff ff 00 00 ff 00 ff 00 ff ff 00 00 ff 00 ff 00 ff 39 00 00 00 00 04 eb 01 30 00];
				gen-panel-mdnie-color-adjustment-mode-cmds = [39 00 00 00 00 83 ec 00 00 00 00 00 00 00 00 00 00 00 00 00 00 00 00 00 00 ff 00 00 07 ff 07 ff 01 00 00 20 00 20 00 20 00 20 00 20 00 20 00 20 00 20 00 20 00 20 00 20 00 20 00 20 00 20 00 20 00 20 00 20 00 20 00 20 00 20 00 20 00 20 00 20 00 ff 00 67 a9 0c 0c 0c 0c 00 aa ab 00 aa ab 00 aa ab 00 aa ab ff 00 00 ff ff 00 ff 00 ff ff ff ff 00 ff ff 00 ff 00 ff 00 00 ff ff 00 ff 00 ff 00 00 ff ff 00 ff 00 ff 00 39 00 00 00 00 04 eb 01 30 00];
				gen-panel-mdnie-dark-screene-mode-cmds = [39 00 00 00 00 83 ec 00 00 00 00 00 00 00 00 00 00 00 00 00 00 00 00 00 00 ff 00 00 07 ff 07 ff 01 00 00 20 00 20 00 20 00 20 00 20 00 20 00 20 00 20 00 20 00 20 00 20 00 20 00 20 00 20 00 20 00 20 00 20 00 20 00 20 00 20 00 20 00 20 00 20 00 ff 00 67 a9 0c 0c 0c 0c 00 aa ab 00 aa ab 00 aa ab 00 aa ab ff 00 00 ff ff 00 ff 00 ff ff ff ff 00 00 00 00 00 00 00 00 00 00 00 00 00 00 00 00 00 00 00 00 00 00 00 00 39 00 00 00 00 04 eb 01 30 00];
				gen-panel-mdnie-gray-scale-cmds = [39 00 00 00 00 83 ec 00 00 00 00 00 00 00 00 00 00 00 00 00 00 00 00 00 00 ff 00 00 07 ff 07 ff 01 00 00 20 00 20 00 20 00 20 00 20 00 20 00 20 00 20 00 20 00 20 00 20 00 20 00 20 00 20 00 20 00 20 00 20 00 20 00 20 00 20 00 20 00 20 00 20 00 ff 00 67 a9 0c 0c 0c 0c 00 aa ab 00 aa ab 00 aa ab 00 aa ab ff 00 00 ff ff 00 ff 00 ff ff ff ff b3 4c b3 4c b3 4c 69 96 69 96 69 96 e2 1d e2 1d e2 1d ff 00 ff 00 ff 00 39 00 00 00 00 04 eb 01 30 00];
				gen-panel-mdnie-gray-scale-negative-cmds = [39 00 00 00 00 83 ec 00 00 00 00 00 00 00 00 00 00 00 00 00 00 00 00 00 00 ff 00 00 07 ff 07 ff 01 00 00 20 00 20 00 20 00 20 00 20 00 20 00 20 00 20 00 20 00 20 00 20 00 20 00 20 00 20 00 20 00 20 00 20 00 20 00 20 00 20 00 20 00 20 00 20 00 ff 00 67 a9 0c 0c 0c 0c 00 aa ab 00 aa ab 00 aa ab 00 aa ab ff 00 00 ff ff 00 ff 00 ff ff ff ff 4c b3 4c b3 4c b3 96 69 96 69 96 69 1d e2 1d e2 1d e2 00 ff 00 ff 00 ff 39 00 00 00 00 04 eb 01 30 00];
				gen-panel-mdnie-hbm-cmds = [39 00 00 00 00 83 ec 00 00 00 00 00 00 00 00 00 00 00 00 00 00 00 00 00 02 ff 00 00 07 ff 07 ff 01 20 00 20 00 20 00 20 00 20 00 20 00 20 00 20 00 20 00 20 00 20 00 20 00 20 00 20 00 20 00 20 00 20 00 20 00 20 00 20 00 20 00 20 00 20 00 20 00 ff 00 67 a9 0c 0c 0c 0c 00 aa ab 00 aa ab 00 aa ab 00 aa ab ff 00 00 ff ff 00 ff 00 ff ff ff ff 00 ff ff 00 ff 00 ff 00 00 ff ff 00 ff 00 ff 00 00 ff ff 00 ff 00 ff 00 39 00 00 00 00 04 eb 01 33 00];
				gen-panel-mdnie-hbm-text-cmds = [39 00 00 00 00 83 ec 00 00 00 00 00 00 00 00 00 00 00 00 00 00 00 00 00 02 ff 00 00 07 ff 07 ff 01 20 00 20 00 20 00 20 00 20 00 20 00 20 00 20 00 20 00 20 00 20 00 20 00 20 00 20 00 20 00 20 00 20 00 20 00 20 00 20 00 20 00 20 00 20 00 20 00 ff 00 67 a9 0c 0c 0c 0c 00 aa ab 00 aa ab 00 aa ab 00 aa ab ff 00 00 ff ff 00 ff 00 ff ff ff ff 00 ff ff 00 ff 00 ff 00 00 ff ff 00 ff 00 ff 00 00 ff ff 00 ff 00 ff 00 39 00 00 00 00 04 eb 01 33 00];
				gen-panel-mdnie-ui-mode-cmds = [39 00 00 00 00 83 ec 00 00 00 00 00 00 00 00 00 00 00 00 00 00 00 00 00 00 ff 00 00 00 a0 00 a0 01 00 00 20 00 20 00 20 00 20 00 20 00 20 00 20 00 20 00 20 00 20 00 20 00 20 00 20 00 20 00 20 00 20 00 20 00 20 00 20 00 20 00 20 00 20 00 20 00 ff 00 67 a9 0c 0c 0c 0c 00 aa ab 00 aa ab 00 aa ab 00 aa ab ff 00 00 ff ff 00 ff 00 ff ff ff ff 00 f9 ef 00 e4 00 ff 00 00 e4 e4 00 f3 00 ee 00 18 ed ff 00 f7 00 ed 00 39 00 00 00 00 04 eb 01 33 00];
				gen-panel-mdnie-video-mode-cmds = [39 00 00 00 00 83 ec 00 00 00 00 00 00 00 00 00 00 00 00 00 00 00 00 00 04 ff 00 04 00 40 00 40 01 00 00 20 00 20 00 20 00 20 00 20 00 20 00 20 00 20 00 20 00 20 00 20 00 20 00 20 00 20 00 20 00 20 00 20 00 20 00 20 00 20 00 20 00 20 00 20 00 ff 00 67 a9 0c 0c 0c 0c 00 aa ab 00 aa ab 00 aa ab 00 aa ab ff 00 00 ff ff 00 ff 00 ff ff ff ff 00 f9 ef 00 e4 00 ff 00 00 e4 e4 00 f3 00 ee 00 18 ed ff 00 f7 00 ed 00 39 00 00 00 00 04 eb 01 33 00];
				gen-panel-mdnie-camera-mode-cmds = [39 00 00 00 00 83 ec 00 00 00 00 00 00 00 00 00 00 00 00 00 00 00 00 00 00 ff 00 00 00 a0 00 a0 01 00 00 20 00 20 00 20 00 20 00 20 00 20 00 20 00 20 00 20 00 20 00 20 00 20 00 20 00 20 00 20 00 20 00 20 00 20 00 20 00 20 00 20 00 20 00 20 00 ff 00 67 a9 0c 0c 0c 0c 00 aa ab 00 aa ab 00 aa ab 00 aa ab ff 00 00 ff ff 00 ff 00 ff ff ff ff 00 f9 ef 00 e4 00 ff 00 00 e4 e4 00 f3 00 ee 00 18 ed ff 00 f7 00 ed 00 39 00 00 00 00 04 eb 01 33 00];
				gen-panel-mdnie-gallery-mode-cmds = [39 00 00 00 00 83 ec 00 00 00 00 00 00 00 00 00 00 00 00 00 00 00 00 00 04 ff 00 04 00 a0 00 a0 01 00 00 20 00 20 00 20 00 20 00 20 00 20 00 20 00 20 00 20 00 20 00 20 00 20 00 20 00 20 00 20 00 20 00 20 00 20 00 20 00 20 00 20 00 20 00 20 00 ff 00 67 a9 0c 0c 0c 0c 00 aa ab 00 aa ab 00 aa ab 00 aa ab ff 00 00 ff ff 00 ff 00 ff ff ff ff 00 f9 ef 00 e4 00 ff 00 00 e4 e4 00 f3 00 ee 00 18 ed ff 00 f7 00 ed 00 39 00 00 00 00 04 eb 01 33 00];
				gen-panel-mdnie-vt-mode-cmds = [39 00 00 00 00 83 ec 00 00 00 00 00 00 00 00 00 00 00 00 00 00 00 00 00 00 ff 00 00 00 a0 00 a0 01 00 00 20 00 20 00 20 00 20 00 20 00 20 00 20 00 20 00 20 00 20 00 20 00 20 00 20 00 20 00 20 00 20 00 20 00 20 00 20 00 20 00 20 00 20 00 20 00 ff 00 67 a9 0c 0c 0c 0c 00 aa ab 00 aa ab 00 aa ab 00 aa ab ff 00 00 ff ff 00 ff 00 ff ff ff ff 00 f9 ef 00 e4 00 ff 00 00 e4 e4 00 f3 00 ee 00 18 ed ff 00 f7 00 ed 00 39 00 00 00 00 04 eb 01 33 00];
				gen-panel-mdnie-browser-mode-cmds = [39 00 00 00 00 83 ec 00 00 00 00 00 00 00 00 00 00 00 00 00 00 00 00 00 00 ff 00 00 00 a0 00 a0 01 00 00 20 00 20 00 20 00 20 00 20 00 20 00 20 00 20 00 20 00 20 00 20 00 20 00 20 00 20 00 20 00 20 00 20 00 20 00 20 00 20 00 20 00 20 00 20 00 ff 00 67 a9 0c 0c 0c 0c 00 aa ab 00 aa ab 00 aa ab 00 aa ab ff 00 00 ff ff 00 ff 00 ff ff ff ff 00 f9 ef 00 e4 00 ff 00 00 e4 e4 00 f3 00 ee 00 18 ed ff 00 f7 00 ed 00 39 00 00 00 00 04 eb 01 33 00];
				gen-panel-mdnie-ebook-mode-cmds = [39 00 00 00 00 83 ec 00 00 00 00 00 00 00 00 00 00 00 00 00 00 00 00 00 00 ff 00 00 00 a0 00 a0 01 00 00 20 00 20 00 20 00 20 00 20 00 20 00 20 00 20 00 20 00 20 00 20 00 20 00 20 00 20 00 20 00 20 00 20 00 20 00 20 00 20 00 20 00 20 00 20 00 ff 00 67 a9 0c 0c 0c 0c 00 aa ab 00 aa ab 00 aa ab 00 aa ab ff 00 00 ff ff 00 ff 00 ff ff ff ff 00 f9 ef 00 e4 00 ff 00 00 e4 e4 00 f3 00 ee 00 18 ed ff 00 f7 00 ed 00 39 00 00 00 00 04 eb 01 33 00];
				gen-panel-mdnie-email-mode-cmds = [39 00 00 00 00 83 ec 00 00 00 00 00 00 00 00 00 00 00 00 00 00 00 00 00 00 ff 00 00 07 ff 07 ff 01 00 00 20 00 20 00 20 00 20 00 20 00 20 00 20 00 20 00 20 00 20 00 20 00 20 00 20 00 20 00 20 00 20 00 20 00 20 00 20 00 20 00 20 00 20 00 20 00 ff 00 67 a9 0c 0c 0c 0c 00 aa ab 00 aa ab 00 aa ab 00 aa ab ff 00 00 ff ff 00 ff 00 ff ff ff ff 00 ff ff 00 ff 00 ff 00 00 ff ff 00 ff 00 ff 00 00 ff ff 00 f4 00 e4 00 39 00 00 00 00 04 eb 01 30 00];
				gen-panel-mdnie-auto-ui-mode-cmds = [39 00 00 00 00 83 ec 00 00 00 00 00 00 00 00 00 00 00 00 00 00 00 00 00 00 ff 00 08 00 a0 00 a0 01 00 00 20 00 20 00 20 00 20 00 20 00 20 00 20 00 20 00 20 00 20 00 20 00 20 00 20 00 20 00 20 00 20 00 20 00 20 00 20 00 20 00 20 00 20 00 20 00 ff 00 6a 9a 25 1a 16 2a 00 37 5a 00 4e c5 00 5d 17 00 30 c3 ff 00 00 ff ff 00 ff 00 ff ff ff ff 00 ff ff 00 ff 00 ff 00 00 ff ff 00 ff 00 ff 00 00 ff ff 00 ff 00 ff 00 39 00 00 00 00 04 eb 01 33 00];
				gen-panel-mdnie-auto-video-mode-cmds = [39 00 00 00 00 83 ec 00 00 00 00 00 00 00 00 00 00 00 00 00 00 00 00 00 07 ff 00 08 00 40 00 40 01 20 00 14 00 14 00 14 00 14 03 9a 03 9a 03 9a 03 9a 07 9e 07 9e 07 9e 07 9e 0a a0 0a a0 0a a0 0a a0 16 a6 16 a6 16 a6 16 a6 05 21 0b 20 87 0f 00 ff 30 67 a9 37 29 19 47 00 25 3d 00 31 f4 00 51 ec 00 1c d8 ff 30 48 ff ff 00 ff 00 ff ff f4 ff 00 ff ff 00 ff 00 ff 00 00 ff ff 00 ff 00 ff 00 00 ff ff 00 ff 00 ff 00 39 00 00 00 00 04 eb 01 33 00];
				gen-panel-mdnie-auto-camera-mode-cmds = [39 00 00 00 00 83 ec 00 00 00 00 00 00 00 00 00 00 00 00 00 00 00 00 00 00 ff 00 08 00 a0 00 a0 01 00 00 20 00 20 00 20 00 20 00 20 00 20 00 20 00 20 00 20 00 20 00 20 00 20 00 20 00 20 00 20 00 20 00 20 00 20 00 20 00 20 00 20 00 20 00 20 00 ff 30 6a 9a 25 1a 16 2a 00 37 5a 00 4e c5 00 5d 17 00 30 c3 ff 08 18 ff f0 00 d8 00 d9 ff ff ff 00 e0 ff 00 f6 00 d8 3b 00 ff d9 00 ff 14 f9 00 00 ff ff 00 ff 00 ff 00 39 00 00 00 00 04 eb 01 30 00];
				gen-panel-mdnie-auto-gallery-mode-cmds = [39 00 00 00 00 83 ec 00 00 00 00 00 00 00 00 00 00 00 00 00 00 00 00 00 04 ff 00 08 00 a0 00 a0 01 00 00 20 00 20 00 20 00 20 00 20 00 20 00 20 00 20 00 20 00 20 00 20 00 20 00 20 00 20 00 20 00 20 00 20 00 20 00 20 00 20 00 20 00 20 00 20 00 ff 30 6a 9a 25 1a 16 2a 00 37 5a 00 4e c5 00 5d 17 00 30 c3 ff 08 18 ff f0 00 d8 00 d9 ff ff ff 00 e0 ff 00 f6 00 d8 3b 00 ff d9 00 ff 14 f9 00 00 ff ff 00 ff 00 ff 00 39 00 00 00 00 04 eb 01 33 00];
				gen-panel-mdnie-auto-vt-mode-cmds = [39 00 00 00 00 83 ec 00 00 00 00 00 00 00 00 00 00 00 00 00 00 00 00 00 00 ff 00 08 00 a0 00 a0 01 00 00 20 00 20 00 20 00 20 00 20 00 20 00 20 00 20 00 20 00 20 00 20 00 20 00 20 00 20 00 20 00 20 00 20 00 20 00 20 00 20 00 20 00 20 00 20 00 ff 00 6a 9a 25 1a 16 2a 00 37 5a 00 4e c5 00 5d 17 00 30 c3 ff 00 00 ff ff 00 ff 00 ff ff ff ff 00 ff ff 00 ff 00 ff 00 00 ff ff 00 ff 00 ff 00 00 ff ff 00 ff 00 ff 00 39 00 00 00 00 04 eb 01 33 00];
				gen-panel-mdnie-auto-browser-mode-cmds = [39 00 00 00 00 83 ec 00 00 00 00 00 00 00 00 00 00 00 00 00 00 00 00 00 00 ff 00 08 00 a0 00 a0 01 00 00 20 00 20 00 20 00 20 00 20 00 20 00 20 00 20 00 20 00 20 00 20 00 20 00 20 00 20 00 20 00 20 00 20 00 20 00 20 00 20 00 20 00 20 00 20 00 ff 30 6a 9a 25 1a 16 2a 00 37 5a 00 4e c5 00 5d 17 00 30 c3 ff 10 28 ff ff 00 ff 00 ff ff ff ff 00 ff ff 00 ff 00 ff 00 00 ff ff 00 ff 00 ff 00 00 ff ff 00 ff 00 ff 00 39 00 00 00 00 04 eb 01 30 00];
				gen-panel-mdnie-auto-ebook-mode-cmds = [39 00 00 00 00 83 ec 00 00 00 00 00 00 00 00 00 00 00 00 00 00 00 00 00 00 ff 00 00 07 ff 07 ff 01 00 00 20 00 20 00 20 00 20 00 20 00 20 00 20 00 20 00 20 00 20 00 20 00 20 00 20 00 20 00 20 00 20 00 20 00 20 00 20 00 20 00 20 00 20 00 20 00 ff 00 67 a9 0c 0c 0c 0c 00 aa ab 00 aa ab 00 aa ab 00 aa ab ff 00 00 ff ff 00 ff 00 ff ff ff ff 00 ff ff 00 ff 00 ff 00 00 ff ff 00 ff 00 ff 00 00 ff ff 00 f4 00 e4 00 39 00 00 00 00 04 eb 01 30 00];
				gen-panel-mdnie-dynamic-ui-mode-cmds = [39 00 00 00 00 83 ec 00 00 00 00 00 00 00 00 00 00 00 00 00 00 00 00 00 03 ff 00 0a 00 a0 00 a0 01 20 00 14 00 14 00 14 00 14 03 9a 03 9a 03 9a 03 9a 07 9e 07 9e 07 9e 07 9e 0a a0 0a a0 0a a0 0a a0 16 a6 16 a6 16 a6 16 a6 05 21 0b 20 87 0f 00 ff 30 67 a9 37 29 19 47 00 25 3d 00 31 f4 00 51 ec 00 1c d8 ff 30 48 ff ff 00 ff 00 ff ff f4 ff 00 ff ff 00 ff 00 ff 00 00 ff ff 00 ff 00 ff 00 00 ff ff 00 ff 00 ff 00 39 00 00 00 00 04 eb 01 33 00];
				gen-panel-mdnie-dynamic-video-mode-cmds = [39 00 00 00 00 83 ec 00 00 00 00 00 00 00 00 00 00 00 00 00 00 00 00 00 07 ff 00 0a 00 40 00 40 01 20 00 14 00 14 00 14 00 14 03 9a 03 9a 03 9a 03 9a 07 9e 07 9e 07 9e 07 9e 0a a0 0a a0 0a a0 0a a0 16 a6 16 a6 16 a6 16 a6 05 21 0b 20 87 0f 00 ff 30 67 a9 37 29 19 47 00 25 3d 00 31 f4 00 51 ec 00 1c d8 ff 30 48 ff ff 00 ff 00 ff ff f4 ff 00 ff ff 00 ff 00 ff 00 00 ff ff 00 ff 00 ff 00 00 ff ff 00 ff 00 ff 00 39 00 00 00 00 04 eb 01 33 00];
				gen-panel-mdnie-dynamic-camera-mode-cmds = [39 00 00 00 00 83 ec 00 00 00 00 00 00 00 00 00 00 00 00 00 00 00 00 00 03 ff 00 0a 00 a0 00 a0 01 20 00 14 00 14 00 14 00 14 03 9a 03 9a 03 9a 03 9a 07 9e 07 9e 07 9e 07 9e 0a a0 0a a0 0a a0 0a a0 16 a6 16 a6 16 a6 16 a6 05 21 0b 20 87 0f 00 ff 30 67 a9 37 29 19 47 00 25 3d 00 31 f4 00 51 ec 00 1c d8 ff 30 48 ff ff 00 ff 00 ff ff f4 ff 00 ff ff 00 ff 00 ff 00 00 ff ff 00 ff 00 ff 00 00 ff ff 00 ff 00 ff 00 39 00 00 00 00 04 eb 01 33 00];
				gen-panel-mdnie-dynamic-gallery-mode-cmds = [39 00 00 00 00 83 ec 00 00 00 00 00 00 00 00 00 00 00 00 00 00 00 00 00 07 ff 00 0a 00 a0 00 a0 01 20 00 14 00 14 00 14 00 14 03 9a 03 9a 03 9a 03 9a 07 9e 07 9e 07 9e 07 9e 0a a0 0a a0 0a a0 0a a0 16 a6 16 a6 16 a6 16 a6 05 21 0b 20 87 0f 00 ff 30 67 a9 37 29 19 47 00 25 3d 00 31 f4 00 51 ec 00 1c d8 ff 30 48 ff ff 00 ff 00 ff ff f4 ff 00 ff ff 00 ff 00 ff 00 00 ff ff 00 ff 00 ff 00 00 ff ff 00 ff 00 ff 00 39 00 00 00 00 04 eb 01 33 00];
				gen-panel-mdnie-dynamic-vt-mode-cmds = [39 00 00 00 00 83 ec 00 00 00 00 00 00 00 00 00 00 00 00 00 00 00 00 00 03 ff 00 0a 00 a0 00 a0 01 20 00 14 00 14 00 14 00 14 03 9a 03 9a 03 9a 03 9a 07 9e 07 9e 07 9e 07 9e 0a a0 0a a0 0a a0 0a a0 16 a6 16 a6 16 a6 16 a6 05 21 0b 20 87 0f 00 ff 30 67 a9 37 29 19 47 00 25 3d 00 31 f4 00 51 ec 00 1c d8 ff 30 48 ff ff 00 ff 00 ff ff f4 ff 00 ff ff 00 ff 00 ff 00 00 ff ff 00 ff 00 ff 00 00 ff ff 00 ff 00 ff 00 39 00 00 00 00 04 eb 01 33 00];
				gen-panel-mdnie-dynamic-browser-mode-cmds = [39 00 00 00 00 83 ec 00 00 00 00 00 00 00 00 00 00 00 00 00 00 00 00 00 03 ff 00 0a 00 a0 00 a0 01 20 00 14 00 14 00 14 00 14 03 9a 03 9a 03 9a 03 9a 07 9e 07 9e 07 9e 07 9e 0a a0 0a a0 0a a0 0a a0 16 a6 16 a6 16 a6 16 a6 05 21 0b 20 87 0f 00 ff 30 67 a9 37 29 19 47 00 25 3d 00 31 f4 00 51 ec 00 1c d8 ff 30 48 ff ff 00 ff 00 ff ff f4 ff 00 ff ff 00 ff 00 ff 00 00 ff ff 00 ff 00 ff 00 00 ff ff 00 ff 00 ff 00 39 00 00 00 00 04 eb 01 33 00];
				gen-panel-mdnie-dynamic-ebook-mode-cmds = [39 00 00 00 00 83 ec 00 00 00 00 00 00 00 00 00 00 00 00 00 00 00 00 00 03 ff 00 0a 00 a0 00 a0 01 20 00 14 00 14 00 14 00 14 03 9a 03 9a 03 9a 03 9a 07 9e 07 9e 07 9e 07 9e 0a a0 0a a0 0a a0 0a a0 16 a6 16 a6 16 a6 16 a6 05 21 0b 20 87 0f 00 ff 30 67 a9 37 29 19 47 00 25 3d 00 31 f4 00 51 ec 00 1c d8 ff 30 48 ff ff 00 ff 00 ff ff f4 ff 00 ff ff 00 ff 00 ff 00 00 ff ff 00 ff 00 ff 00 00 ff ff 00 ff 00 ff 00 39 00 00 00 00 04 eb 01 33 00];
				gen-panel-mdnie-natural-ui-mode-cmds = [39 00 00 00 00 83 ec 00 00 00 00 00 00 00 00 00 00 00 00 00 00 00 00 00 02 ff 00 00 00 a0 00 a0 01 40 00 20 00 20 00 20 00 20 00 20 00 20 00 20 00 20 00 20 00 20 00 20 00 20 00 20 00 20 00 20 00 20 00 20 00 20 00 20 00 20 00 20 00 20 00 20 00 ff 00 67 a9 0c 0c 0c 0c 00 aa ab 00 aa ab 00 aa ab 00 aa ab ff 00 00 ff ff 00 ff 00 ff ff ff ff 8c d5 f4 16 ec 15 de 64 1a ef de 28 f3 1c ef 11 50 e5 ff 00 f7 00 ed 00 39 00 00 00 00 04 eb 01 33 00];
				gen-panel-mdnie-natural-video-mode-cmds = [39 00 00 00 00 83 ec 00 00 00 00 00 00 00 00 00 00 00 00 00 00 00 00 00 06 ff 00 04 00 40 00 40 01 40 00 20 00 20 00 20 00 20 00 20 00 20 00 20 00 20 00 20 00 20 00 20 00 20 00 20 00 20 00 20 00 20 00 20 00 20 00 20 00 20 00 20 00 20 00 20 00 ff 00 67 a9 0c 0c 0c 0c 00 aa ab 00 aa ab 00 aa ab 00 aa ab ff 00 00 ff ff 00 ff 00 ff ff ff ff 8c d5 f4 16 ec 15 de 64 1a ef de 28 f3 1c ef 11 50 e5 ff 00 f7 00 ed 00 39 00 00 00 00 04 eb 01 33 00];
				gen-panel-mdnie-natural-camera-mode-cmds = [39 00 00 00 00 83 ec 00 00 00 00 00 00 00 00 00 00 00 00 00 00 00 00 00 02 ff 00 00 00 a0 00 a0 01 40 00 20 00 20 00 20 00 20 00 20 00 20 00 20 00 20 00 20 00 20 00 20 00 20 00 20 00 20 00 20 00 20 00 20 00 20 00 20 00 20 00 20 00 20 00 20 00 ff 00 67 a9 0c 0c 0c 0c 00 aa ab 00 aa ab 00 aa ab 00 aa ab ff 00 00 ff ff 00 ff 00 ff ff ff ff 8c d5 f4 16 ec 15 de 64 1a ef de 28 f3 1c ef 11 50 e5 ff 00 f7 00 ed 00 39 00 00 00 00 04 eb 01 33 00];
				gen-panel-mdnie-natural-gallery-mode-cmds = [39 00 00 00 00 83 ec 00 00 00 00 00 00 00 00 00 00 00 00 00 00 00 00 00 06 ff 00 04 00 a0 00 a0 01 40 00 20 00 20 00 20 00 20 00 20 00 20 00 20 00 20 00 20 00 20 00 20 00 20 00 20 00 20 00 20 00 20 00 20 00 20 00 20 00 20 00 20 00 20 00 20 00 ff 00 67 a9 0c 0c 0c 0c 00 aa ab 00 aa ab 00 aa ab 00 aa ab ff 00 00 ff ff 00 ff 00 ff ff ff ff 8c d5 f4 16 ec 15 de 64 1a ef de 28 f3 1c ef 11 50 e5 ff 00 f7 00 ed 00 39 00 00 00 00 04 eb 01 33 00];
				gen-panel-mdnie-natural-vt-mode-cmds = [39 00 00 00 00 83 ec 00 00 00 00 00 00 00 00 00 00 00 00 00 00 00 00 00 02 ff 00 00 00 a0 00 a0 01 40 00 20 00 20 00 20 00 20 00 20 00 20 00 20 00 20 00 20 00 20 00 20 00 20 00 20 00 20 00 20 00 20 00 20 00 20 00 20 00 20 00 20 00 20 00 20 00 ff 00 67 a9 0c 0c 0c 0c 00 aa ab 00 aa ab 00 aa ab 00 aa ab ff 00 00 ff ff 00 ff 00 ff ff ff ff 8c d5 f4 16 ec 15 de 64 1a ef de 28 f3 1c ef 11 50 e5 ff 00 f7 00 ed 00 39 00 00 00 00 04 eb 01 33 00];
				gen-panel-mdnie-natural-browser-mode-cmds = [39 00 00 00 00 83 ec 00 00 00 00 00 00 00 00 00 00 00 00 00 00 00 00 00 02 ff 00 00 00 a0 00 a0 01 40 00 20 00 20 00 20 00 20 00 20 00 20 00 20 00 20 00 20 00 20 00 20 00 20 00 20 00 20 00 20 00 20 00 20 00 20 00 20 00 20 00 20 00 20 00 20 00 ff 00 67 a9 0c 0c 0c 0c 00 aa ab 00 aa ab 00 aa ab 00 aa ab ff 00 00 ff ff 00 ff 00 ff ff ff ff 8c d5 f4 16 ec 15 de 64 1a ef de 28 f3 1c ef 11 50 e5 ff 00 f7 00 ed 00 39 00 00 00 00 04 eb 01 33 00];
				gen-panel-mdnie-natural-ebook-mode-cmds = [39 00 00 00 00 83 ec 00 00 00 00 00 00 00 00 00 00 00 00 00 00 00 00 00 02 ff 00 00 00 a0 00 a0 01 40 00 20 00 20 00 20 00 20 00 20 00 20 00 20 00 20 00 20 00 20 00 20 00 20 00 20 00 20 00 20 00 20 00 20 00 20 00 20 00 20 00 20 00 20 00 20 00 ff 00 67 a9 0c 0c 0c 0c 00 aa ab 00 aa ab 00 aa ab 00 aa ab ff 00 00 ff ff 00 ff 00 ff ff ff ff 8c d5 f4 16 ec 15 de 64 1a ef de 28 f3 1c ef 11 50 e5 ff 00 f7 00 ed 00 39 00 00 00 00 04 eb 01 33 00];
				gen-panel-mdnie-movie-ui-mode-cmds = [39 00 00 00 00 83 ec 00 00 00 00 00 00 00 00 00 00 00 00 00 00 00 00 00 00 ff 00 00 07 ff 07 ff 01 83 00 20 00 20 00 20 00 20 00 20 00 20 00 20 00 20 00 20 00 20 00 20 00 20 00 20 00 20 00 20 00 20 00 20 00 20 00 20 00 20 00 20 00 20 00 20 00 ff 00 67 a9 0c 0c 0c 0c 00 aa ab 00 aa ab 00 aa ab 00 aa ab d5 2c 2a ff f5 63 fe 4a ff ff f9 f8 00 ff ff 00 ff 00 ff 00 00 ff ff 00 ff 00 ff 00 00 ff ff 00 ff 00 ff 00 39 00 00 00 00 04 eb 01 30 00];
				gen-panel-mdnie-movie-video-mode-cmds = [39 00 00 00 00 83 ec 00 00 00 00 00 00 00 00 00 00 00 00 00 00 00 00 00 00 ff 00 00 07 ff 07 ff 01 83 00 20 00 20 00 20 00 20 00 20 00 20 00 20 00 20 00 20 00 20 00 20 00 20 00 20 00 20 00 20 00 20 00 20 00 20 00 20 00 20 00 20 00 20 00 20 00 ff 00 67 a9 0c 0c 0c 0c 00 aa ab 00 aa ab 00 aa ab 00 aa ab d5 2c 2a ff f5 63 fe 4a ff ff f9 f8 00 ff ff 00 ff 00 ff 00 00 ff ff 00 ff 00 ff 00 00 ff ff 00 ff 00 ff 00 39 00 00 00 00 04 eb 01 30 00];
				gen-panel-mdnie-movie-camera-mode-cmds = [39 00 00 00 00 83 ec 00 00 00 00 00 00 00 00 00 00 00 00 00 00 00 00 00 00 ff 00 08 00 a0 00 a0 01 00 00 20 00 20 00 20 00 20 00 20 00 20 00 20 00 20 00 20 00 20 00 20 00 20 00 20 00 20 00 20 00 20 00 20 00 20 00 20 00 20 00 20 00 20 00 20 00 ff 30 6a 9a 25 1a 16 2a 00 37 5a 00 4e c5 00 5d 17 00 30 c3 ff 38 48 ff f0 00 d8 00 d9 ff ff ff 00 e0 ff 00 f6 00 d8 3b 00 ff d9 00 ff 14 f9 00 00 ff ff 00 ff 00 ff 00 39 00 00 00 00 04 eb 01 30 00];
				gen-panel-mdnie-movie-gallery-mode-cmds = [39 00 00 00 00 83 ec 00 00 00 00 00 00 00 00 00 00 00 00 00 00 00 00 00 00 ff 00 00 07 ff 07 ff 01 83 00 20 00 20 00 20 00 20 00 20 00 20 00 20 00 20 00 20 00 20 00 20 00 20 00 20 00 20 00 20 00 20 00 20 00 20 00 20 00 20 00 20 00 20 00 20 00 ff 30 67 a9 0c 0c 0c 0c 00 aa ab 00 aa ab 00 aa ab 00 aa ab d5 2c 2a ff f5 63 fe 4a ff ff f9 f8 00 ff ff 00 ff 00 ff 00 00 ff ff 00 ff 00 ff 00 00 ff ff 00 ff 00 ff 00 39 00 00 00 00 04 eb 01 30 00];
				gen-panel-mdnie-movie-vt-mode-cmds = [39 00 00 00 00 83 ec 00 00 00 00 00 00 00 00 00 00 00 00 00 00 00 00 00 00 ff 00 00 07 ff 07 ff 01 83 00 20 00 20 00 20 00 20 00 20 00 20 00 20 00 20 00 20 00 20 00 20 00 20 00 20 00 20 00 20 00 20 00 20 00 20 00 20 00 20 00 20 00 20 00 20 00 ff 30 67 a9 0c 0c 0c 0c 00 aa ab 00 aa ab 00 aa ab 00 aa ab d5 2c 2a ff f5 63 fe 4a ff ff f9 f8 00 ff ff 00 ff 00 ff 00 00 ff ff 00 ff 00 ff 00 00 ff ff 00 ff 00 ff 00 39 00 00 00 00 04 eb 01 30 00];
				gen-panel-mdnie-movie-browser-mode-cmds = [39 00 00 00 00 83 ec 00 00 00 00 00 00 00 00 00 00 00 00 00 00 00 00 00 00 ff 00 00 07 ff 07 ff 01 83 00 20 00 20 00 20 00 20 00 20 00 20 00 20 00 20 00 20 00 20 00 20 00 20 00 20 00 20 00 20 00 20 00 20 00 20 00 20 00 20 00 20 00 20 00 20 00 ff 30 67 a9 0c 0c 0c 0c 00 aa ab 00 aa ab 00 aa ab 00 aa ab d5 2c 2a ff f5 63 fe 4a ff ff f9 f8 00 ff ff 00 ff 00 ff 00 00 ff ff 00 ff 00 ff 00 00 ff ff 00 ff 00 ff 00 39 00 00 00 00 04 eb 01 30 00];
				gen-panel-mdnie-movie-ebook-mode-cmds = [39 00 00 00 00 83 ec 00 00 00 00 00 00 00 00 00 00 00 00 00 00 00 00 00 00 ff 00 00 07 ff 07 ff 01 83 00 20 00 20 00 20 00 20 00 20 00 20 00 20 00 20 00 20 00 20 00 20 00 20 00 20 00 20 00 20 00 20 00 20 00 20 00 20 00 20 00 20 00 20 00 20 00 ff 30 67 a9 0c 0c 0c 0c 00 aa ab 00 aa ab 00 aa ab 00 aa ab d5 2c 2a ff f5 63 fe 4a ff ff f9 f8 00 ff ff 00 ff 00 ff 00 00 ff ff 00 ff 00 ff 00 00 ff ff 00 ff 00 ff 00 39 00 00 00 00 04 eb 01 30 00];

				gen-panel-mdnie-cal {
					cal-reg = [ec];
					cal-offset = [7c 7e 80];
					cal-modes = <0x00 0x04>;
					cal-linear-equation = <0xfffffddd 0x1f7 0x1f 0xfffffe2d 0x1bf 0xffffffe7 0xc9 0x27 0xffffb6e2 0x20b 0xad 0xffffd0b1>;
					cal-tune-value = [ff f9 f9 ff fa fe f8 f5 ff ff fd fa ff ff ff f9 fa ff fc ff f8 fa ff fa f9 ff ff];
				};
			};
		};
	};

	keypad@40250000 {
		compatible = "sprd,sci-keypad";
		reg = <0x40250000 0x1000>;
		gpios = <0x34 0x02 0x00 0x34 0x0a 0x00>;
		interrupts = <0x00 0x24 0x00>;
		sprd,keypad-num-rows = <0x02>;
		sprd,keypad-num-columns = <0x03>;
		sprd,keypad-rows-choose-hw = <0x30000>;
		sprd,keypad-cols-choose-hw = <0x700>;
		sprd,debounce_time = <0x1388>;
		linux,keypad-no-autorepeat;

		key_volume_up {
			keypad,row = <0x00>;
			keypad,column = <0x00>;
			linux,code = <0x73>;
		};

		key_volume_up1 {
			keypad,row = <0x00>;
			keypad,column = <0x01>;
			linux,code = <0x73>;
		};

		key_home {
			keypad,row = <0x00>;
			keypad,column = <0x02>;
			linux,code = <0xac>;
		};
	};

	sprd_vsp@60900000 {
		compatible = "sprd,sprd_vsp";
		reg = <0x60900000 0xc000>;
		interrupts = <0x00 0x2b 0x00>;
		clock-names = "clk_mm_i\0clk_vsp";
		clocks = <0x23 0x40>;
		version = <0x03>;
	};

	sprd_jpg {
		compatible = "sprd,sprd_jpg";
		reg = <0x60b00000 0x8000>;
		interrupts = <0x00 0x2a 0x00>;
		clock-names = "clk_mm_i\0clk_jpg";
		clocks = <0x23 0x41>;
	};

	sprd_vpp@61000000 {
		compatible = "sprd,sprd_vpp";
		reg = <0x61000000 0x4000>;
		interrupts = <0x00 0x2b 0x00>;
		clock-names = "clk_mm_i\0clk_vpp";
		clocks = <0x23 0x42>;
	};

	sprd_coda7l@62100000 {
		compatible = "sprd,sprd_coda7l";
		reg = <0x62100000 0x4000>;
		interrupts = <0x00 0x2b 0x00>;
		clock-names = "clk_mm_i\0clk_coda7_axi\0clk_coda7_cc\0clk_coda7_apb";
		clocks = <0x23 0x43 0x44 0x45>;
		power-regs-info = <0x402b01a4 0x00 0x402b00c4 0x0f>;
	};

	i2c@70500000 {
		compatible = "sprd,i2c";
		interrupts = <0x00 0x0b 0x00>;
		reg = <0x70500000 0x1000>;
		#address-cells = <0x01>;
		#size-cells = <0x00>;

		sensor_main@0x3c {
			compatible = "sprd,sensor_main";
			reg = <0x3c>;
		};

		sensor_sub@0x21 {
			compatible = "sprd,sensor_sub";
			reg = <0x21>;
		};
	};

	i2c@70600000 {
		compatible = "sprd,i2c";
		interrupts = <0x00 0x0c 0x00>;
		reg = <0x70600000 0x1000>;
		#address-cells = <0x01>;
		#size-cells = <0x00>;

		ist30xxc@50 {
			compatible = "imagis,ist30xxc";
			reg = <0x50>;
			imagis,power-src = "vddsim2";
			gpios = <0x35 0x8e 0x00>;
			interrupt-parent = <0x35>;
			interrupts = <0x8e 0x01>;
			imagis,irq-flag = <0x2002>;
			imagis,irq-gpio = <0x35 0x8e 0x00>;
			imagis,avdd-volt = <0x2dc6c0>;
			imagis,max-x = <0x2d0>;
			imagis,max-y = <0x500>;
			imagis,max-w = <0x0f>;
			imagis,chip-id = <0x38c>;
			imagis,chip-name = "IST3038C";
			imagis,chip-code = <0x03>;
			imagis,max-node = <0x240>;
			imagis,tkey = <0x01>;
			imagis,octa-hw = <0x01>;
		};
	};

	i2c@70700000 {
		compatible = "sprd,i2c";
		interrupts = <0x00 0x0d 0x00>;
		reg = <0x70700000 0x1000>;
		#address-cells = <0x01>;
		#size-cells = <0x00>;

		sm5701-i2c@49 {
			compatible = "sm,sm5701";
			reg = <0x49>;

			chargermfd {

				charger {
					compatible = "sm,sm5701-charger";
					chgen-gpio = <0x35 0xd7 0x00>;
					chgirq-gpio = <0x35 0x5c 0x00>;
				};
			};

			leds_sm5701 {
				compatible = "sm,leds_sm5701";
				flashen-gpio = <0x35 0x36 0x00>;
				flashtorch-gpio = <0x35 0x9c 0x00>;
			};
		};

		bma_acc@18 {
			compatible = "bma2x2";
			reg = <0x18>;
			interrupt-parent = <0x35>;
			interrupts = <0x87 0x00>;
			bma2x2,gpio_int1 = <0x35 0x87 0x00>;
			bma2x2,accel_place = <0x03>;
		};
	};

	i2c@70800000 {
		compatible = "sprd,i2c";
		interrupts = <0x00 0x0e 0x00>;
		reg = <0x70800000 0x1000>;
		#address-cells = <0x01>;
		#size-cells = <0x00>;

		pn547@2B {
			compatible = "pn547";
			reg = <0x2b>;
			pinctrl-names = "default";
			interrupt-parent = <0x35>;
			interrupts = <0x33 0x00>;
			pn547,firm-gpio = <0x35 0x59 0x00>;
			pn547,ven-gpio = <0x35 0x55 0x00>;
			pn547,irq-gpio = <0x35 0x33 0x00>;
			pn547,ldo_flag = <0x00>;
			pn547,gpio_power;
			pn547,pvdd_en = <0x35 0x58 0x00>;
		};
	};

	sprd_dcam {
		compatible = "sprd,sprd_dcam";
		interrupts = <0x00 0x2d 0x00>;
		reg = <0x60800000 0x100000>;
		clock-names = "clk_mm_i\0clk_dcam";
		clocks = <0x23 0x46>;
	};

	sprd_scale {
		compatible = "sprd,sprd_scale";
	};

	sprd_rotation {
		compatible = "sprd,sprd_rotation";
	};

	sprd_sensor {
		compatible = "sprd,sprd_sensor";
		reg = <0x60c00000 0x100000>;
		gpios = <0x35 0x2c 0x00 0x35 0x00 0x00 0x35 0x2d 0x00 0x35 0x00 0x00 0x35 0x86 0x00 0x35 0x86 0x00 0x35 0x00 0x00 0x35 0x00 0x00 0x35 0x00 0x00 0x35 0x00 0x00 0x35 0x00 0x00 0x35 0x00 0x00 0x35 0x00 0x00 0x35 0x00 0x00 0x35 0x00 0x00 0x35 0x00 0x00 0x35 0x00 0x00 0x35 0x00 0x00 0x35 0x00 0x00 0x35 0x00 0x00>;
		vdds = "vddcammot\0vddcama\0vddcamd\0vddcamd\0vddcammot\0vddcama\0vddcamd\0vddcamd";
		clock-names = "clk_mm_i\0clk_sensor\0clk_ccir\0clk_dcam\0clk_dcam_mipi";
		clocks = <0x23 0x47 0x48 0x46 0x49>;
	};

	sprd_isp {
		compatible = "sprd,sprd_isp";
		reg = <0x60a00000 0x100000>;
		clock-names = "clk_mm_i\0clk_isp";
		clocks = <0x23 0x4a>;
	};

	sprd_dma_copy {
		compatible = "sprd,sprd_dma_copy";
	};

	gps {
		compatible = "broadcom,bcm47520";
		gps-pwr-en = <0x35 0x0b 0x00>;
		gps-regulator = "vddcamio";
		tcxo-regulator = "vddsdio";
		tcxo-regulator-volt = <0x325aa0>;
	};

	fb@20800000 {
		compatible = "sprd,sprdfb";
		reg = <0x20800000 0x1000 0x21800000 0x1000>;
		interrupts = <0x00 0x2e 0x00 0x00 0x30 0x00 0x00 0x31 0x00>;
		clock-names = "dispc_clk_parent\0dispc_dbi_clk_parent\0dispc_dpi_clk_parent\0dispc_emc_clk_parent\0dispc_clk\0dispc_dbi_clk\0dispc_dpi_clk\0dispc_emc_clk\0fb_spi_clock\0fb_spi_clock_parent";
		clocks = <0x20 0x20 0x1c 0x1e 0x4b 0x4c 0x4d 0x4e 0x4f 0x07>;
		clock-src = <0xf424000 0xf424000 0x16e36000>;
		dpi_clk_div = <0x07>;
		sprd,fb_use_reservemem;
		sprd,fb_mem = <0x9eb74000 0xa8c000>;
	};

	gsp@20a00000 {
		compatible = "sprd,gsp";
		reg = <0x20a00000 0x1000>;
		interrupts = <0x00 0x33 0x00>;
		clock-names = "clk_gsp\0clk_gsp_emc\0clk_gsp_parent\0clk_aon_apb";
		clocks = <0x50 0x51 0x20 0x1e>;
		gsp_mmu_ctrl_base = <0x20b08000>;
	};

	sprd_fm@40270000 {
		compatible = "sprd,sprd_fm";
		reg = <0x40270000 0x1000>;
	};

	sipc@0x87800000 {
		compatible = "sprd,sipc";
		reg = <0x87800000 0x500000>;
		#address-cells = <0x01>;
		#size-cells = <0x01>;
		ranges = <0x9600000 0x89600000 0x4380000 0x7800000 0x87800000 0x500000 0x1440000 0x8aa40000 0x1000 0x5000c000 0x5000c000 0x1000>;

		sipc_lte@0x09600000 {
			sprd,name = "sipc-lte";
			sprd,dst = <0x05>;
			mailbox,core = <0x07>;
			reg = <0x9600000 0x4380000 0x7800000 0x500000 0x1440000 0x1000>;
		};

		sipc_pmsys@0x5000c000 {
			sprd,name = "sipc-pmsys";
			sprd,dst = <0x06>;
			mailbox,core = <0x01>;
			reg = <0x5000c000 0x1000>;
		};
	};

	saudio_lte {
		compatible = "sprd,saudio";
		sprd,saudio-dst-id = <0x05>;
		sprd,ctrl_channel = <0x0a>;
		sprd,playback_channel = <0x0b>;
		sprd,capture_channel = <0x0c>;
		sprd,monitor_channel = <0x0d>;
		sprd,saudio-names = "saudiolte";
	};

	saudio_voip {
		compatible = "sprd,saudio";
		sprd,saudio-dst-id = <0x05>;
		sprd,ctrl_channel = <0x0e>;
		sprd,playback_channel = <0x0f>;
		sprd,capture_channel = <0x10>;
		sprd,monitor_channel = <0x11>;
		sprd,saudio-names = "saudiovoip";
	};

	spipe_lte {
		compatible = "sprd,spipe";
		sprd,name = "spipe_lte";
		sprd,dst = <0x05>;
		sprd,channel = <0x04>;
		sprd,ringnr = <0x0b>;
		sprd,size-rxbuf = <0x1000>;
		sprd,size-txbuf = <0x1000>;
	};

	slog_lte {
		compatible = "sprd,spipe";
		sprd,name = "slog_lte";
		sprd,dst = <0x05>;
		sprd,channel = <0x05>;
		sprd,ringnr = <0x01>;
		sprd,size-rxbuf = <0x40000>;
		sprd,size-txbuf = <0x8000>;
	};

	sdiag_lte {
		compatible = "sprd,spipe";
		sprd,name = "sdiag_lte";
		sprd,dst = <0x05>;
		sprd,channel = <0x15>;
		sprd,ringnr = <0x01>;
		sprd,size-rxbuf = <0x40000>;
		sprd,size-txbuf = <0x8000>;
	};

	stty_lte {
		compatible = "sprd,spipe";
		sprd,name = "stty_lte";
		sprd,dst = <0x05>;
		sprd,channel = <0x06>;
		sprd,ringnr = <0x20>;
		sprd,size-rxbuf = <0x800>;
		sprd,size-txbuf = <0x800>;
	};

	sipx_lte {
		compatible = "sprd,sipx";
		sprd,name = "sipx_lte";
		sprd,dst = <0x05>;
		sprd,dl-pool = <0x400>;
		sprd,dl-ack-pool = <0x200>;
		sprd,ul-pool = <0x400>;
		sprd,ul-ack-pool = <0x400>;
	};

	seth0_lte {
		compatible = "sprd,seth";
		sprd,name = "rmnet0";
		sprd,dst = <0x05>;
		sprd,channel = <0x07>;
		sprd,blknum = <0x200>;
		sprd,poolsize = <0x10>;
	};

	seth1_lte {
		compatible = "sprd,seth";
		sprd,name = "rmnet1";
		sprd,dst = <0x05>;
		sprd,channel = <0x08>;
		sprd,blknum = <0x200>;
		sprd,poolsize = <0x10>;
	};

	seth2_lte {
		compatible = "sprd,seth";
		sprd,name = "rmnet2";
		sprd,dst = <0x05>;
		sprd,channel = <0x09>;
		sprd,blknum = <0x200>;
		sprd,poolsize = <0x10>;
	};

	seth3_lte {
		compatible = "sprd,seth";
		sprd,name = "rmnet3";
		sprd,dst = <0x05>;
		sprd,channel = <0x12>;
		sprd,blknum = <0x200>;
		sprd,poolsize = <0x10>;
	};

	seth4_lte {
		compatible = "sprd,seth";
		sprd,name = "rmnet4";
		sprd,dst = <0x05>;
		sprd,channel = <0x13>;
		sprd,blknum = <0x200>;
		sprd,poolsize = <0x10>;
	};

	seth5_lte {
		compatible = "sprd,seth";
		sprd,name = "rmnet5";
		sprd,dst = <0x05>;
		sprd,channel = <0x14>;
		sprd,blknum = <0x200>;
		sprd,poolsize = <0x10>;
	};

	seth6_lte {
		compatible = "sprd,seth";
		sprd,name = "rmnet6";
		sprd,dst = <0x05>;
		sprd,channel = <0x18>;
		sprd,blknum = <0x200>;
		sprd,poolsize = <0x10>;
	};

	seth7_lte {
		compatible = "sprd,seth";
		sprd,name = "rmnet7";
		sprd,dst = <0x05>;
		sprd,channel = <0x19>;
		sprd,blknum = <0x200>;
		sprd,poolsize = <0x10>;
	};

	scproc@0x50800000 {
		compatible = "sprd,scproc";
		sprd,name = "cppmic";
		sprd,ctrl-reg = <0x114 0xff 0xb0 0xff>;
		sprd,ctrl-mask = <0x01 0xf0000 0x100 0xf0000>;
		sprd,iram-data = <0xe59f0000 0xe12fff10 0x00>;
		reg = <0x50800000 0x8000 0x50800000 0x00 0x402e0000 0x400 0x402e0000 0x400 0x402b0000 0x100 0x402b0000 0x100>;
		interrupts = <0x00 0x7c 0x00>;
		#address-cells = <0x01>;
		#size-cells = <0x01>;
		ranges = <0x00 0x50800000 0x8000>;

		modem@0x0 {
			cproc,name = "modem";
			reg = <0x00 0x5400>;
		};
	};

	scproc@0x89600000 {
		compatible = "sprd,scproc";
		sprd,name = "cptl";
		sprd,ctrl-reg = <0x0c 0xcc 0xb0 0x78>;
		sprd,ctrl-mask = <0x100000 0x140000 0x02 0x01>;
		sprd,iram-data = <0xe59f0000 0xe12fff10 0x8ab88000>;
		reg = <0x89600000 0x4380000 0x50001000 0x0c 0x402e0000 0x100 0x402b0000 0x100 0x402b0000 0x100 0x402b0000 0x100 0x8aa41000 0x800>;
		interrupts = <0x00 0x54 0x00>;
		#address-cells = <0x01>;
		#size-cells = <0x01>;
		ranges = <0x1588000 0x8ab88000 0xc30000 0x20000 0x89620000 0x2e0000 0x300000 0x89900000 0x1c0000 0x3b00000 0x8d100000 0x300000 0x1441800 0x8aa41800 0x800 0x1442000 0x8aa42000 0x90000 0x14d2000 0x8aad2000 0xb4000>;

		modem@0x1588000 {
			cproc,name = "modem";
			reg = <0x1588000 0xc30000>;
		};

		dsp@0x20000 {
			cproc,name = "tgdsp";
			reg = <0x20000 0x2e0000>;
		};

		dsp@0x300000 {
			cproc,name = "ldsp";
			reg = <0x300000 0x1c0000>;
		};

		modem@0x3B00000 {
			cproc,name = "warm";
			reg = <0x3b00000 0x300000>;
		};

		cpcmdline@0x1441800 {
			cproc,name = "cpcmdline";
			reg = <0x1441800 0x800>;
		};

		fixnv@0x1442000 {
			cproc,name = "fixnv";
			reg = <0x1442000 0x90000>;
		};

		runnv@0x14D2000 {
			cproc,name = "runnv";
			reg = <0x14d2000 0xb4000>;
		};
	};

	usb@20200000 {
		compatible = "sprd,usb";
		interrupts = <0x00 0x37 0x00>;
		ngpios = <0x01>;
		gpios = <0x34 0x00 0x00>;
		reg = <0x20200000 0x1000>;
		tune_value = <0x78e33>;
		usb-supply = <0x52>;
		#address-cells = <0x01>;
		#size-cells = <0x00>;
	};

	usb_notifier {
		compatible = "samsung,usb-notifier";
		booster-name = "sm5701_booster";
	};

	thermal@402F0000 {
		compatible = "sprd,sprd-thermal";
		id = <0x00>;
		interrupts = <0x00 0x1a 0x00>;
		reg = <0x402f0000 0x1000>;
		trip_points_active = <0x1f 0x38 0x3c 0x5a 0x6e>;
		trip_points_lowoff = <0x00 0x1d 0x2e 0x32 0x50>;
		trip_points_critical = <0x6e>;
		trip_num = <0x06>;
	};

	thermal1@402F0000 {
		compatible = "sprd,sprd-thermal";
		id = <0x01>;
		interrupts = <0x00 0x1a 0x00>;
		reg = <0x402f0000 0x1000>;
		trip_points_active = <0x6e>;
		trip_points_lowoff = <0x5a>;
		trip_points_critical = <0x6e>;
		trip_num = <0x02>;
	};

	thermal@40038280 {
		compatible = "sprd,sprd-thermal";
		id = <0x02>;
		interrupt-parent = <0x29>;
		interrupts = <0x09 0x00>;
		reg = <0x40038280 0x1000>;
		trip_points_active = <0x6e>;
		trip_points_lowoff = <0x5a>;
		trip_points_critical = <0x6e>;
		trip_num = <0x02>;
	};

	sprd_cpu_cooling {
		compatible = "sprd,sprd-cpu-cooling";
		id = <0x00>;
		max_freq = <0x149970 0x16e360 0x149970 0xdbba0 0xbb800>;
		max_core = <0x04 0x04 0x04 0x04 0x01>;
		state_num = <0x05>;
		vddarm_update0 = <0x00 0x149970 0x100590>;
		vddarm_update1 = <0x01 0x149970 0xf4240>;
		vddarm_nr = <0x02 0x03 0x03>;
	};

	spi@70a00000 {
		compatible = "sprd,sprd-spi";
		interrupts = <0x00 0x07 0x00>;
		reg = <0x70a00000 0x1000>;
		clock-names = "clk_spi0";
		#address-cells = <0x01>;
		#size-cells = <0x00>;
	};

	spi@70b00000 {
		compatible = "sprd,sprd-spi";
		interrupts = <0x00 0x08 0x00>;
		reg = <0x70b00000 0x1000>;
		clock-names = "clk_spi1";
		#address-cells = <0x01>;
		#size-cells = <0x00>;
	};

	spi@70c00000 {
		compatible = "sprd,sprd-spi";
		interrupts = <0x00 0x09 0x00>;
		reg = <0x70c00000 0x1000>;
		clock-names = "clk_spi2";
		#address-cells = <0x01>;
		#size-cells = <0x00>;
	};

	dma-controller@20100000 {
		compatible = "sprd,sharkl64-dma";
		#dma-cells = <0x01>;
		#dma-channels = <0x40>;
		aon_offset = <0x20>;
		reg = <0x00 0x20100000 0x00 0x4000 0x00 0x40100000 0x00 0x4000>;
		interrupts = <0x00 0x32 0x00 0x00 0x46 0x00>;
	};

	adc@40038300 {
		compatible = "sprd,sprd-adc";
		reg = <0x40038300 0x400>;
	};

	hwspinlock0@20d00000 {
		compatible = "sprd,sprd-hwspinlock";
		reg = <0x20d00000 0x1000>;
	};

	hwspinlock1@40060000 {
		compatible = "sprd,sprd-hwspinlock";
		reg = <0x40060000 0x1000>;
	};

	itm_wlan {
		compatible = "sprd,itm_wlan";
	};

	dmac@20100000 {
		compatible = "sprd,sprd-dma";
		interrupts = <0x00 0x32 0x00>;
		reg = <0x00 0x20100000 0x00 0x4000>;
	};

	gpu@60000000 {
		compatible = "arm,mali-400\0arm,mali-utgard";
		reg = <0x60000000 0x10000>;
		interrupts = <0x00 0x27 0x00 0x00 0x27 0x00 0x00 0x27 0x00 0x00 0x27 0x00 0x00 0x27 0x00 0x00 0x27 0x00 0x00 0x27 0x00>;
		interrupt-names = "IRQGP\0IRQGPMMU\0IRQPP0\0IRQPPMMU0\0IRQPP1\0IRQPPMMU1\0IRQPMU";
		pmu_domain_config = <0x1000 0x1000 0x1000 0x00 0x00 0x00 0x00 0x00 0x00 0x1000 0x00 0x00>;
		pmu_switch_delay = <0xffff>;
		clocks = <0x53 0x54 0x19 0x1a 0x20 0x1b 0x1c 0x08>;
		clock-names = "clk_gpu_axi\0clk_gpu\0clk_153m6\0clk_192m\0clk_256m\0clk_307m2\0clk_384m\0clk_512m";
		freq-list-len = <0x04>;
		freq-lists = <0x25800 0x02 0x01 0x3e800 0x04 0x01 0x5dc00 0x06 0x01 0x7d000 0x07 0x01>;
		freq-default = <0x01>;
		freq-9 = <0x02>;
		freq-8 = <0x01>;
		freq-7 = <0x00>;
		freq-5 = <0x00>;
		freq-range-max = <0x03>;
		freq-range-min = <0x00>;
	};

	ion {
		compatible = "sprd,ion-sprd";
		#address-cells = <0x01>;
		#size-cells = <0x00>;

		sprd,ion-heap@1 {
			reg = <0x01>;
			reg-names = "ion_heap_system";
			sprd,ion-heap-type = <0x00>;
			sprd,ion-heap-mem = <0x00 0x00>;
		};

		sprd,ion-heap@2 {
			reg = <0x02>;
			reg-names = "ion_heap_carveout_mm";
			sprd,ion-heap-type = <0x02>;
			sprd,ion-heap-mem = <0x9b23b000 0x3939000>;
		};

		sprd,ion-heap@3 {
			reg = <0x03>;
			reg-names = "ion_heap_carveout_overlay";
			sprd,ion-heap-type = <0x02>;
			sprd,ion-heap-mem = <0x9f600000 0x708000>;
		};
	};

	sprd_iommu@20b00000 {
		compatible = "sprd,sprd_iommu";
		func-name = "sprd_iommu_gsp";
		reg = <0x10000000 0x2000000 0x20b00000 0x8000 0x20b08000 0x8000>;
		reg_name = "iova\0pgt\0ctrl_reg";
		clock-names = "clk_gsp_emc\0clk_153m6\0clk_gsp";
		clocks = <0x51 0x19 0x50>;
		status = "ok";
	};

	sprd_iommu@60f00000 {
		compatible = "sprd,sprd_iommu";
		func-name = "sprd_iommu_mm";
		reg = <0x20000000 0x8000000 0x60f00000 0x20000 0x60f20000 0x2000>;
		reg_name = "iova\0pgt\0ctrl_reg";
		clock-names = "clk_mmu\0clk_mm_i";
		clocks = <0x55 0x23>;
		status = "ok";
	};

	sprd-io-base {
		#address-cells = <0x01>;
		#size-cells = <0x01>;
		ranges = <0x00 0x00 0x80000000>;

		ahb {
			compatible = "sprd,ahb";
			reg = <0x20e00000 0x10000>;
		};

		hwlock0 {
			compatible = "sprd,hwlock0";
			reg = <0x20d00000 0x1000>;
		};

		aonapb {
			compatible = "sprd,aonapb";
			reg = <0x402e0000 0x10000>;
		};

		apbreg {
			compatible = "sprd,apbreg";
			reg = <0x71300000 0x10000>;
		};

		pmu {
			compatible = "sprd,pmu";
			reg = <0x402b0000 0x10000>;
		};

		mmahb {
			compatible = "sprd,mmahb";
			reg = <0x60d00000 0x4000>;
		};

		mmckg {
			compatible = "sprd,mmckg";
			reg = <0x60e00000 0x1000>;
		};

		codecahb {
			compatible = "sprd,codecahb";
			reg = <0x62000000 0x1000>;
		};

		adislave {
			compatible = "sprd,adislave";
			reg = <0x40038000 0x1000>;
		};

		gpuapb {
			compatible = "sprd,gpuapb";
			reg = <0x60100000 0x1000>;
		};

		apbckg {
			compatible = "sprd,apbckg";
			reg = <0x21500000 0x1000>;
		};

		aonckg {
			compatible = "sprd,aonckg";
			reg = <0x402d0000 0x1000>;
		};

		gpuckg {
			compatible = "sprd,gpuckg";
			reg = <0x60200000 0x1000>;
		};

		core {
			compatible = "sprd,core";
			reg = <0x12000000 0x10000>;
		};

		int {
			compatible = "sprd,int";
			reg = <0x40200000 0x1000>;
		};

		intc0 {
			compatible = "sprd,intc0";
			reg = <0x71400000 0x1000>;
		};

		intc1 {
			compatible = "sprd,intc1";
			reg = <0x71500000 0x1000>;
		};

		intc2 {
			compatible = "sprd,intc2";
			reg = <0x71600000 0x1000>;
		};

		intc3 {
			compatible = "sprd,intc3";
			reg = <0x71700000 0x1000>;
		};

		send_mbox {
			compatible = "sprd,send_mbox";
			reg = <0x400a0000 0x1000>;
		};

		recv_mbox {
			compatible = "sprd,recv_mbox";
			reg = <0x400a8000 0x1000>;
		};

		uidefuse {
			compatible = "sprd,uidefuse";
			reg = <0x40240000 0x1000>;
		};

		isp {
			compatible = "sprd,isp";
			reg = <0x60a00000 0x8000>;
		};

		ca7wdg {
			compatible = "sprd,ca7wdg";
			reg = <0x40310000 0x1000>;
		};

		csi2 {
			compatible = "sprd,csi2";
			reg = <0x60c00000 0x1000>;
		};

		wdg {
			compatible = "sprd,wdg";
			reg = <0x40290000 0x1000>;
		};

		ipi {
			compatible = "sprd,ipi";
			reg = <0x402c0000 0x1000>;
		};

		dcam {
			compatible = "sprd,dcam";
			reg = <0x60800000 0x10000>;
		};

		syscnt {
			compatible = "sprd,syscnt";
			reg = <0x40230000 0x1000>;
		};

		dma0 {
			compatible = "sprd,dma0";
			reg = <0x20100000 0x4000>;
		};

		pub {
			compatible = "sprd,pub";
			reg = <0x30020000 0x10000>;
		};

		pin {
			compatible = "sprd,pin";
			reg = <0x402a0000 0x1000>;
		};

		mailbox {
			compatible = "sprd,mailbox";
			reg = <0x400a0000 0x10000>;
		};

		axibm0 {
			compatible = "sprd,axibm0";
			reg = <0x00 0x30040000 0x00 0x20000>;
			interrupts = <0x00 0x56 0x00>;
		};
	};

	wdt@40290000 {
		compatible = "sprd,sprd-wdt";
		reg = <0x40290000 0x1000 0x40310000 0x1000>;
		interrupts = <0x00 0x7c 0x00>;
	};

	sprd-marlin {
		compatible = "sprd,marlin";
		gpios = <0x35 0x61 0x00 0x35 0x84 0x00 0x35 0x85 0x00 0x35 0x1e 0x00 0x35 0x82 0x00>;
		cp-rfctl-offset = <0x94>;
		vdd-download = "vddcon";
		vdd-pa = "vddwifipa";
		clk-name = "clk_aux0";
		sdhci-name = "sdio_wifi";
	};

	sprd_bm {
		compatible = "sprd,sprd_bm";
		reg = <0x30040000 0xa0000 0x20f00000 0x300000>;
		interrupts = <0x00 0x56 0x00>;
		sprd,bm_status = <0x01>;
		sprd,bm_count = <0x0a 0x0b>;
		sprd,cpu_chn = <0x00 0x01>;
		sprd,disp_chn = <0x01 0x01>;
		sprd,gpu_chn = <0x02 0x01>;
		sprd,ap_zip_chn = <0x03 0x01>;
		sprd,mm_chn = <0x04 0x01>;
		sprd,cp0_arm0_1_chn = <0x05 0x01>;
		sprd,cp0_dsp_chn = <0x06 0x00>;
		sprd,cp1_lte_chn = <0x07 0x01>;
		sprd,cp1_dsp_chn = <0x08 0x01>;
		sprd,cp1_arm_chn = <0x09 0x01>;
		sprd,ap_dap_chn = <0x00 0x00>;
		sprd,ap_cpu_chn = <0x00 0x01>;
		sprd,ap_dma_w_chn = <0x00 0x02>;
		sprd,ap_dma_r_chn = <0x00 0x03>;
		sprd,ap_sdio_0_chn = <0x01 0x00>;
		sprd,ap_sdio_1_chn = <0x01 0x01>;
		sprd,ap_sdio_2_chn = <0x01 0x02>;
		sprd,ap_emmc_chn = <0x01 0x03>;
		sprd,ap_nandc_chn = <0x02 0x00>;
		sprd,ap_otg_chn = <0x02 0x01>;
		sprd,ap_hsic_chn = <0x02 0x02>;
	};

	input_booster {
		status = "disabled";
		compatible = "input_booster";
		#address-cells = <0x01>;
		#size-cells = <0x00>;

		booster_key@1 {
			input_booster,label = "KEY";
			input_booster,type = <0x00>;
			input_booster,levels = <0x01>;
			input_booster,cpu_freqs = <0x149970>;
			input_booster,core_num_lock = <0x02>;
			input_booster,head_times = <0xc8>;
			input_booster,tail_times = <0x00>;
		};

		booster_key@2 {
			input_booster,label = "TOUCHKEY";
			input_booster,type = <0x01>;
			input_booster,levels = <0x01>;
			input_booster,cpu_freqs = <0xdbba0>;
			input_booster,core_num_lock = <0x02>;
			input_booster,head_times = <0x00>;
			input_booster,tail_times = <0x12c>;
		};

		booster_key@3 {
			input_booster,label = "TOUCH";
			input_booster,type = <0x02>;
			input_booster,levels = <0x01 0x02 0x03>;
			input_booster,cpu_freqs = <0x149970 0x149970 0xdbba0>;
			input_booster,core_num_lock = <0x02>;
			input_booster,head_times = <0xc8 0xc8 0x00>;
			input_booster,tail_times = <0x00 0x00 0x12c>;
		};

		booster_key@4 {
			input_booster,label = "MULTITOUCH";
			input_booster,type = <0x03>;
			input_booster,levels = <0x01 0x02>;
			input_booster,cpu_freqs = <0x16e360 0xbb800>;
			input_booster,core_num_lock = <0x02>;
			input_booster,head_times = <0x3e8 0x00>;
			input_booster,tail_times = <0x00 0x1f4>;
		};

		booster_key@5 {
			input_booster,label = "KEYBOARD";
			input_booster,type = <0x04>;
			input_booster,levels = <0x01 0x02>;
			input_booster,cpu_freqs = <0x149970 0x149970>;
			input_booster,core_num_lock = <0x02>;
			input_booster,head_times = <0xc8 0xc8>;
			input_booster,tail_times = <0x00 0x00>;
		};

		booster_key@6 {
			input_booster,label = "MOUSE";
			input_booster,type = <0x05>;
			input_booster,levels = <0x01 0x02>;
			input_booster,cpu_freqs = <0x149970 0xdbba0>;
			input_booster,core_num_lock = <0x02>;
			input_booster,head_times = <0xc8 0x00>;
			input_booster,tail_times = <0x00 0x12c>;
		};

		booster_key@7 {
			input_booster,label = "MOUSE WHEEL";
			input_booster,type = <0x06>;
			input_booster,levels = <0x01 0x02>;
			input_booster,cpu_freqs = <0x149970 0x00>;
			input_booster,core_num_lock = <0x02>;
			input_booster,head_times = <0xc8 0x00>;
			input_booster,tail_times = <0x00 0x00>;
		};

		booster_key@8 {
			input_booster,label = "PEN HOVER";
			input_booster,type = <0x07>;
			input_booster,levels = <0x01 0x02>;
			input_booster,cpu_freqs = <0x149970 0xdbba0>;
			input_booster,core_num_lock = <0x02>;
			input_booster,head_times = <0xc8 0x00>;
			input_booster,tail_times = <0x00 0x12c>;
		};
	};
};
